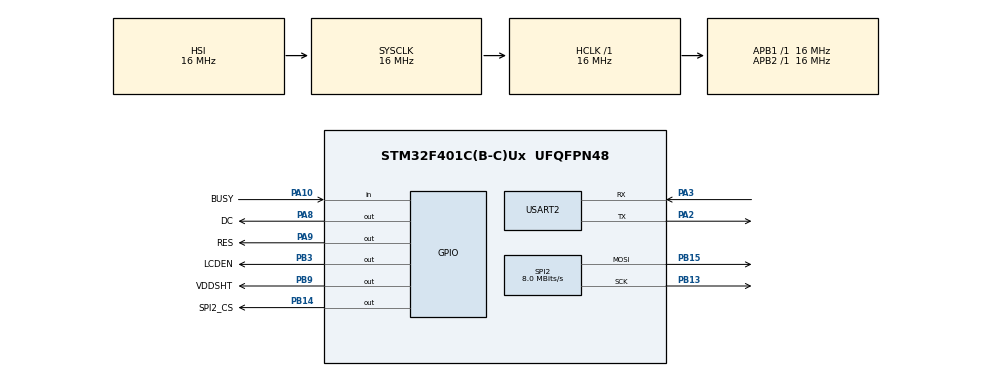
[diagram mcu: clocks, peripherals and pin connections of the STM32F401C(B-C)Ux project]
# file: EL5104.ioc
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Mcu.Family=STM32F4
Mcu.Name=STM32F401C(B-C)Ux
Mcu.Package=UFQFPN48
NVIC.PriorityGroup=NVIC_PRIORITYGROUP_4
NVIC.USART2_IRQn=true\:7\:0\:true\:false\:true\:true\:true
PA10.GPIO_Label=BUSY
PA10.GPIO_PuPd=GPIO_PULLUP
PA10.Signal=GPIO_Input
PA13.Mode=Serial_Wire
PA13.Signal=SYS_JTMS-SWDIO
PA14.Mode=Serial_Wire
PA14.Signal=SYS_JTCK-SWCLK
PA2.Mode=Asynchronous
PA2.Signal=USART2_TX
PA3.Mode=Asynchronous
PA3.Signal=USART2_RX
PA8.GPIO_Label=DC
PA8.Signal=GPIO_Output
PA9.GPIO_Label=RES
PA9.Signal=GPIO_Output
PB13.Mode=TX_Only_Simplex_Unidirect_Master
PB13.Signal=SPI2_SCK
PB14.GPIO_Label=SPI2_CS
PB14.Signal=GPIO_Output
PB15.Mode=TX_Only_Simplex_Unidirect_Master
PB15.Signal=SPI2_MOSI
PB3.GPIO_Label=LCDEN
PB3.GPIO_ModeDefaultOutputPP=GPIO_MODE_OUTPUT_PP
PB3.GPIO_PuPd=GPIO_NOPULL
PB3.PinState=GPIO_PIN_SET
PB3.Signal=GPIO_Output
PB6.Signal=I2C1_SCL
PB7.Signal=I2C1_SDA
PB9.GPIO_Label=VDDSHT
PB9.PinState=GPIO_PIN_SET
PB9.Signal=GPIO_Output
PC14-OSC32_IN.Mode=LSE-External-Oscillator
PC14-OSC32_IN.Signal=RCC_OSC32_IN
PC15-OSC32_OUT.Mode=LSE-External-Oscillator
PC15-OSC32_OUT.Signal=RCC_OSC32_OUT
ProjectManager.HeapSize=0x200
ProjectManager.StackSize=0x400
ProjectManager.TargetToolchain=MDK-ARM V5.27
RCC.AHBFreq_Value=16000000
RCC.APB1Freq_Value=16000000
RCC.APB2Freq_Value=16000000
RCC.CortexFreq_Value=16000000
RCC.HSE_VALUE=25000000
RCC.HSI_VALUE=16000000
RCC.SYSCLKFreq_VALUE=16000000
RCC.VCOOutputFreq_Value=192000000
SPI2.CalculateBaudRate=8.0 MBits/s
SPI2.Direction=SPI_DIRECTION_2LINES
SPI2.Mode=SPI_MODE_MASTER
SPI2.VirtualType=VM_MASTER
USART2.VirtualMode=VM_ASYNC
VP_RTC_VS_RTC_Activate.Mode=RTC_Enabled
VP_RTC_VS_RTC_Calendar.Mode=RTC_Calendar
board=custom

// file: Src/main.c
/* USER CODE BEGIN Header */
/**
  ******************************************************************************
  * @file           : main.c
  * @brief          : Main program body
  ******************************************************************************
  * @attention
  *
  * <h2><center>&copy; Copyright (c) 2020 STMicroelectronics.
  * All rights reserved.</center></h2>
  *
  * This software component is licensed by ST under BSD 3-Clause license,
  * the "License"; You may not use this file except in compliance with the
  * License. You may obtain a copy of the License at:
  *                        opensource.org/licenses/BSD-3-Clause
  *
  ******************************************************************************
  */
/* USER CODE END Header */

#include "main.h"
#include "rtc.h"
#include "spi.h"
#include "usart.h"
#include "gpio.h"

/* USER CODE BEGIN PV */
const uint8_t gImage_black1[15000];
/* USER CODE END PV */

void SystemClock_Config(void);

/* USER CODE BEGIN 0 */
void EPD_W21_WriteCMD(uint8_t cmd)
{
	HAL_GPIO_WritePin(GPIOB, SPI2_CS_Pin, GPIO_PIN_RESET);
	HAL_GPIO_WritePin(GPIOA, DC_Pin, GPIO_PIN_RESET);
	HAL_SPI_Transmit(&hspi2, &cmd, 1, 0xff);
	HAL_GPIO_WritePin(GPIOB, SPI2_CS_Pin, GPIO_PIN_SET);
}

void EPD_W21_WriteDATA(uint8_t dat)
{
	HAL_GPIO_WritePin(GPIOB, SPI2_CS_Pin, GPIO_PIN_RESET);
	HAL_GPIO_WritePin(GPIOA, DC_Pin, GPIO_PIN_SET);
	HAL_SPI_Transmit(&hspi2, &dat, 1, 0xff);
	HAL_GPIO_WritePin(GPIOB, SPI2_CS_Pin, GPIO_PIN_SET);
}

void lcd_chkstatus(void)
{
//	while(isEPD_W21_BUSY);  //1:BUSY,0:Free
//	HAL_Delay(200);
}

void EPD_init(void)
{
	  HAL_GPIO_WritePin(GPIOA, RES_Pin, GPIO_PIN_RESET);
    HAL_Delay(100);
	  HAL_GPIO_WritePin(GPIOA, RES_Pin, GPIO_PIN_SET);

  	EPD_W21_WriteCMD(0x12);			//SWRESET
		//lcd_chkstatus(); //waiting for the electronic paper IC to release the idle signal
	  HAL_Delay(100);
		EPD_W21_WriteCMD(0x74);
		EPD_W21_WriteDATA(0x54);
		EPD_W21_WriteCMD(0x7E);
		EPD_W21_WriteDATA(0x3B);
		EPD_W21_WriteCMD(0x2B);  // Reduce glitch under ACVCOM
		EPD_W21_WriteDATA(0x04);
		EPD_W21_WriteDATA(0x63);

		EPD_W21_WriteCMD(0x0C);  // Soft start setting
		EPD_W21_WriteDATA(0x8B);
		EPD_W21_WriteDATA(0x9C);
		EPD_W21_WriteDATA(0x96);
		EPD_W21_WriteDATA(0x0F);

		EPD_W21_WriteCMD(0x01);  // Set MUX as 300
		EPD_W21_WriteDATA(0x2B);
		EPD_W21_WriteDATA(0x01);
		EPD_W21_WriteDATA(0x00);

		EPD_W21_WriteCMD(0x11);  // Data entry mode
		EPD_W21_WriteDATA(0x01);
		EPD_W21_WriteCMD(0x44);
		EPD_W21_WriteDATA(0x00); // RAM x address start at 0
		EPD_W21_WriteDATA(0x31); // RAM x address end at 31h(49+1)*8->400
		EPD_W21_WriteCMD(0x45);
		EPD_W21_WriteDATA(0x2B);   // RAM y address start at 12Bh
		EPD_W21_WriteDATA(0x01);
		EPD_W21_WriteDATA(0x00); // RAM y address end at 00h
		EPD_W21_WriteDATA(0x00);
		EPD_W21_WriteCMD(0x3C); // board
		EPD_W21_WriteDATA(0x01); // HIZ

		EPD_W21_WriteCMD(0x18);
		EPD_W21_WriteDATA(0X80);
		EPD_W21_WriteCMD(0x22);
		EPD_W21_WriteDATA(0XB1);	//Load Temperature and waveform setting.
		EPD_W21_WriteCMD(0x20);
		//lcd_chkstatus(); //waiting for the electronic paper IC to release the idle signal
		HAL_Delay(400);

		EPD_W21_WriteCMD(0x4E);
		EPD_W21_WriteDATA(0x00);
		EPD_W21_WriteCMD(0x4F);
		EPD_W21_WriteDATA(0x2B);
		EPD_W21_WriteDATA(0x01);
}
void EPD_refresh(void)
{
		EPD_W21_WriteCMD(0x22);			//DISPLAY REFRESH
		EPD_W21_WriteDATA(0xC7);
		EPD_W21_WriteCMD(0x20);
		//lcd_chkstatus(); //waiting for the electronic paper IC to release the idle signal
		HAL_Delay(1000);
}
void EPD_sleep(void)
{
    EPD_W21_WriteCMD(0X10);  	//deep sleep
		EPD_W21_WriteDATA(0x01);
}

void PIC_display(const unsigned char* picData_BW,const unsigned char* picData_R)
{
    unsigned int i;
		EPD_W21_WriteCMD(0x24);	       //Transfer BW data
	  for(i=0;i<15000;i++)
	{
	  EPD_W21_WriteDATA(~(*picData_BW));
	  picData_BW++;
	}
		EPD_W21_WriteCMD(0x26);		     //Transfer RED data
	  for(i=0;i<15000;i++)
	{
	  EPD_W21_WriteDATA(0);
	  picData_R++;
	}

}
void PIC_display_Clean(void)
{
    unsigned int i;
		EPD_W21_WriteCMD(0x24);	       //Transfer BW data
	  for(i=0;i<15000;i++)
	{
	  EPD_W21_WriteDATA(0xff);
	}

		EPD_W21_WriteCMD(0x26);		     //Transfer RED data
	  for(i=0;i<15000;i++)
	{
	  EPD_W21_WriteDATA(0x00);
	}
}

/* USER CODE END 0 */

int main(void)
{

  /* MCU Configuration--------------------------------------------------------*/

  /* Reset of all peripherals, Initializes the Flash interface and the Systick. */
  HAL_Init();

  /* Configure the system clock */
  SystemClock_Config();

  /* Initialize all configured peripherals */
  MX_GPIO_Init();
  MX_RTC_Init();
  MX_SPI2_Init();
  MX_USART2_UART_Init();
  /* USER CODE BEGIN 2 */
  HAL_GPIO_WritePin(GPIOB, LCDEN_Pin, GPIO_PIN_RESET);
  /* USER CODE END 2 */

  /* Infinite loop */
  /* USER CODE BEGIN WHILE */
	EPD_init(); //EPD init
	PIC_display(gImage_black1,gImage_black1);//EPD_picture1
	EPD_refresh();//EPD_refresh
	EPD_sleep();//EPD_sleep,Sleep instruction is necessary, please do not delete!!!
	HAL_Delay(80);
  while (1)
  {

		//EPD_Clean
//		EPD_init(); //EPD init
//	  PIC_display_Clean();//EPD_Clean
//		EPD_refresh();//EPD_refresh
//		EPD_sleep();//EPD_sleep,Sleep instruction is necessary, please do not delete!!!
//		HAL_Delay(80);
    /* USER CODE END WHILE */

  }
}

void SystemClock_Config(void)
{
  RCC_OscInitTypeDef RCC_OscInitStruct = {0};
  RCC_ClkInitTypeDef RCC_ClkInitStruct = {0};
  RCC_PeriphCLKInitTypeDef PeriphClkInitStruct = {0};

  /** Configure the main internal regulator output voltage
  */
  __HAL_RCC_PWR_CLK_ENABLE();
  __HAL_PWR_VOLTAGESCALING_CONFIG(PWR_REGULATOR_VOLTAGE_SCALE2);
  /** Initializes the CPU, AHB and APB busses clocks
  */
  RCC_OscInitStruct.OscillatorType = RCC_OSCILLATORTYPE_HSI|RCC_OSCILLATORTYPE_LSI;
  RCC_OscInitStruct.HSIState = RCC_HSI_ON;
  RCC_OscInitStruct.HSICalibrationValue = RCC_HSICALIBRATION_DEFAULT;
  RCC_OscInitStruct.LSIState = RCC_LSI_ON;
  RCC_OscInitStruct.PLL.PLLState = RCC_PLL_NONE;
  if (HAL_RCC_OscConfig(&RCC_OscInitStruct) != HAL_OK)
  {
    Error_Handler();
  }
  /** Initializes the CPU, AHB and APB busses clocks
  */
  RCC_ClkInitStruct.ClockType = RCC_CLOCKTYPE_HCLK|RCC_CLOCKTYPE_SYSCLK
                              |RCC_CLOCKTYPE_PCLK1|RCC_CLOCKTYPE_PCLK2;
  RCC_ClkInitStruct.SYSCLKSource = RCC_SYSCLKSOURCE_HSI;
  RCC_ClkInitStruct.AHBCLKDivider = RCC_SYSCLK_DIV1;
  RCC_ClkInitStruct.APB1CLKDivider = RCC_HCLK_DIV1;
  RCC_ClkInitStruct.APB2CLKDivider = RCC_HCLK_DIV1;

  if (HAL_RCC_ClockConfig(&RCC_ClkInitStruct, FLASH_LATENCY_0) != HAL_OK)
  {
    Error_Handler();
  }
  PeriphClkInitStruct.PeriphClockSelection = RCC_PERIPHCLK_RTC;
  PeriphClkInitStruct.RTCClockSelection = RCC_RTCCLKSOURCE_LSI;
  if (HAL_RCCEx_PeriphCLKConfig(&PeriphClkInitStruct) != HAL_OK)
  {
    Error_Handler();
  }
}

/* USER CODE BEGIN 4 */
const uint8_t gImage_black1[15000]  = {
0X00,0X00,0X04,0X14,0X22,0X78,0X00,0X04,0X10,0X00,0X00,0X43,0X06,0X80,0X0E,0X05,
0X04,0X22,0X10,0X00,0X89,0X04,0X00,0X40,0X00,0X30,0X09,0X08,0X80,0X84,0X00,0X48,
0X22,0XA0,0X00,0X09,0X04,0X08,0X03,0X04,0X00,0X0E,0X00,0X00,0X00,0X00,0X00,0X00,
0X00,0X00,0X00,0X00,0X0E,0X2C,0XA2,0X78,0X01,0X02,0X80,0X00,0X02,0X46,0X04,0X08,
0X07,0X06,0X00,0X02,0X80,0X20,0X80,0X03,0X00,0X08,0X05,0X08,0X08,0X40,0X40,0X0E,
0X0C,0X02,0X23,0X50,0X11,0X88,0X48,0X00,0X01,0XE8,0X08,0X06,0X00,0X00,0X00,0X00,
0X00,0X00,0X00,0X00,0X00,0X00,0X1E,0XBA,0X12,0XE0,0X00,0X10,0X44,0X88,0X00,0X04,
0X0C,0X00,0X0E,0X50,0XC0,0XA0,0X00,0X50,0X94,0X00,0X00,0X02,0X02,0X23,0X08,0X02,
0XC0,0X04,0X01,0X04,0X09,0X11,0X01,0X04,0X04,0X00,0X00,0XD8,0X22,0X07,0X00,0X00,
0X00,0X00,0X00,0X00,0X00,0X00,0X00,0X00,0X1C,0X1D,0X60,0XE0,0X25,0X26,0XE0,0X01,
0X00,0X08,0X18,0X20,0X87,0X00,0X00,0X00,0X81,0X01,0X30,0X0A,0X20,0X02,0X84,0X42,
0X00,0X80,0X00,0X03,0X00,0X00,0X0B,0X04,0X00,0X04,0X00,0X04,0X10,0XE0,0X00,0X07,
0X00,0X00,0X00,0X00,0X00,0X00,0X00,0X00,0X00,0X00,0X1E,0X40,0X29,0XC0,0X01,0X0B,
0X87,0X02,0X0E,0X00,0X98,0X40,0X0F,0X02,0X00,0X40,0X24,0X00,0X06,0X4C,0X60,0X10,
0X20,0X20,0X40,0X00,0X00,0X01,0X00,0X11,0X10,0X80,0X00,0X89,0X42,0X00,0X10,0X74,
0X10,0X07,0X80,0X00,0X00,0X00,0X00,0X00,0X00,0X00,0X00,0X00,0X39,0X40,0X12,0XE0,
0XB3,0X82,0XC1,0X91,0X60,0X01,0X19,0X00,0X06,0X00,0X00,0X50,0XD4,0X88,0X00,0X01,
0X40,0X10,0X00,0X02,0X00,0X00,0X02,0X02,0X80,0X40,0X14,0X88,0X80,0X00,0X00,0X10,
0X80,0X78,0X00,0X17,0X80,0X00,0X00,0X00,0X00,0X00,0X00,0X00,0X00,0X00,0X3A,0X24,
0X11,0XC0,0X04,0X56,0X08,0X10,0X80,0X88,0X18,0X00,0X06,0X20,0X15,0X08,0X00,0X00,
0X00,0X20,0X0B,0X00,0X00,0X00,0X1C,0X20,0X19,0X82,0X30,0X00,0X04,0XC0,0X22,0X00,
0X10,0X00,0X00,0X68,0X0C,0X83,0X80,0X00,0X00,0X00,0X00,0X00,0X00,0X00,0X00,0X00,
0X1A,0XBE,0X1F,0X80,0X10,0X00,0XC6,0X08,0X05,0X00,0X30,0X00,0X07,0X04,0X00,0X68,
0XC0,0X40,0X04,0X01,0X00,0X40,0X80,0X00,0X04,0X00,0X08,0X08,0X08,0X05,0X04,0X42,
0X00,0X01,0X21,0X08,0X00,0X38,0X00,0X01,0XC0,0X00,0X00,0X00,0X00,0X00,0X00,0X00,
0X00,0X00,0X3C,0X18,0X4B,0XC0,0X00,0X92,0XEC,0X61,0X8A,0X04,0X35,0X04,0X67,0X00,
0X00,0X04,0X00,0X00,0X04,0X01,0X00,0X00,0X0C,0X10,0X00,0X09,0X1A,0X2A,0X12,0X44,
0X01,0XE8,0X90,0X2C,0X02,0X01,0X04,0X1E,0XE4,0X31,0XC0,0X00,0X00,0X00,0X00,0X00,
0X00,0X00,0X00,0X00,0X38,0X24,0XA7,0X01,0X00,0X00,0X48,0X02,0X00,0X00,0X30,0X00,
0XFF,0X02,0XC0,0X20,0X80,0X00,0X04,0X00,0X00,0X41,0X83,0X00,0X01,0X00,0X80,0X00,
0X00,0X01,0X01,0X60,0X90,0X00,0X00,0X00,0X00,0X0E,0X04,0X45,0XC0,0X00,0X00,0X00,
0X00,0X00,0X00,0X00,0X00,0X00,0X3A,0X20,0X4F,0X00,0X03,0X0C,0X61,0X00,0X80,0X01,
0X40,0X00,0X0F,0X10,0X29,0X01,0X00,0X48,0X00,0X0C,0X24,0X30,0X08,0X50,0X02,0X04,
0X00,0X01,0X00,0X00,0X00,0X70,0X20,0X10,0XC2,0X02,0X04,0X5E,0X85,0X80,0XE0,0X00,
0X00,0X00,0X00,0X00,0X00,0X00,0X00,0X00,0XBC,0X55,0X2E,0X01,0X00,0X98,0X01,0X01,
0XC2,0X00,0X40,0X00,0X47,0X20,0XA0,0X10,0X00,0X00,0X04,0X80,0X22,0X01,0X00,0X10,
0X02,0X00,0X00,0X23,0X00,0X00,0X50,0X30,0X02,0X10,0X00,0X04,0X20,0X5F,0X43,0X00,
0XE0,0X00,0X00,0X00,0X00,0X00,0X00,0X00,0X00,0X00,0X38,0X10,0X7C,0X00,0X01,0X05,
0X82,0X80,0X82,0X88,0X60,0X08,0X07,0X84,0X00,0X00,0X40,0X00,0X80,0X21,0X02,0X90,
0X00,0X00,0X02,0X02,0X00,0X03,0X24,0X00,0X88,0X10,0X00,0X00,0X08,0X01,0X30,0X17,
0X20,0X00,0X60,0X00,0X00,0X00,0X00,0X00,0X00,0X00,0X00,0X00,0X38,0XB4,0X5E,0X00,
0X05,0X11,0X00,0X00,0X00,0X02,0XC0,0X00,0X1F,0XA0,0X00,0X02,0X41,0X20,0X83,0X02,
0X00,0X11,0X00,0X28,0X4B,0X01,0X04,0X03,0X02,0X00,0X00,0X90,0X03,0X00,0X00,0X40,
0X90,0X47,0X80,0X80,0X70,0X00,0X00,0X00,0X00,0X00,0X00,0X00,0X00,0X00,0X38,0XD6,
0XDC,0X00,0X25,0X9C,0X62,0X01,0X28,0X00,0XC0,0X40,0X0F,0X88,0X00,0X00,0X00,0X20,
0X80,0X00,0X10,0X10,0X84,0X00,0X02,0X44,0XAA,0X41,0X80,0X00,0X00,0XB8,0X08,0X00,
0X08,0X06,0X04,0X03,0XCA,0X80,0X70,0X00,0X00,0X00,0X00,0X00,0X00,0X00,0X00,0X00,
0X1C,0X45,0X9C,0X00,0X40,0X00,0X00,0X00,0X05,0X00,0X84,0X04,0X8B,0X80,0X00,0X0C,
0X10,0X01,0X00,0X10,0X00,0X60,0X80,0X04,0X03,0X21,0X00,0X25,0X80,0X0D,0X08,0X18,
0X12,0X80,0X00,0X05,0X04,0X01,0XE0,0X80,0X30,0X00,0X00,0X00,0X00,0X00,0X00,0X00,
0X00,0X00,0X1D,0X2E,0X38,0X04,0X00,0XFD,0XC8,0X00,0X04,0X01,0X80,0X06,0X1B,0X80,
0X00,0X00,0X08,0X00,0X10,0X80,0X00,0X02,0XA6,0X40,0X02,0X00,0X00,0X43,0XE0,0X00,
0X04,0X0C,0X00,0X14,0X00,0X82,0X01,0X01,0XE0,0XC0,0X78,0X00,0X00,0X00,0X00,0X00,
0X00,0X00,0X00,0X00,0X1E,0X8A,0XB8,0X00,0X0D,0X08,0X54,0X10,0X04,0X01,0X01,0X45,
0X07,0X80,0X61,0X01,0X00,0X02,0X06,0X30,0X00,0X50,0X20,0X08,0X03,0X02,0X00,0X01,
0X84,0X01,0X00,0X4D,0X04,0X24,0X00,0X00,0X00,0X00,0XD1,0X60,0X30,0X00,0X00,0X00,
0X00,0X00,0X00,0X00,0X00,0X00,0X0E,0X80,0X70,0X00,0X00,0X00,0XA4,0X01,0X10,0X03,
0X90,0X02,0XC3,0XC0,0X40,0X00,0XA0,0X08,0X80,0X20,0X42,0XB0,0X3A,0X00,0X03,0X00,
0X00,0X81,0XC0,0X12,0X00,0X5C,0X02,0X00,0X01,0X84,0X08,0X80,0X98,0XC0,0X38,0X00,
0X00,0X00,0X00,0X00,0X00,0X00,0X00,0X00,0X1E,0X9E,0X70,0X00,0X09,0X01,0X52,0X10,
0X00,0X01,0XA0,0X20,0X8D,0XD0,0X00,0X90,0X70,0XB5,0X5A,0X00,0X00,0X08,0X2E,0X40,
0X03,0X30,0X08,0X03,0XE0,0X02,0X00,0X26,0X00,0X40,0X90,0X40,0X04,0X00,0XDC,0X20,
0X38,0X00,0X00,0X00,0X00,0X00,0X00,0X00,0X00,0X00,0X00,0X5B,0XF0,0X00,0X01,0XCA,
0X53,0X80,0X08,0XCB,0X04,0X21,0X81,0XC0,0X04,0X04,0X00,0X50,0X42,0X40,0X08,0X00,
0X08,0X00,0X03,0X58,0X82,0XC1,0XE5,0X00,0X00,0X02,0X01,0X08,0X20,0X20,0X55,0X14,
0XCC,0X38,0X18,0X00,0X00,0X00,0X00,0X00,0X00,0X00,0X00,0X00,0X0F,0X25,0XF0,0X00,
0X01,0X39,0X44,0X18,0X2C,0X83,0X02,0X15,0X09,0XC0,0X12,0X88,0X00,0X04,0X10,0X40,
0X00,0X00,0X10,0X80,0X03,0X82,0X39,0X01,0XF8,0X00,0X00,0X07,0X80,0X20,0X00,0X09,
0X40,0X04,0X8E,0X12,0X1C,0X00,0X00,0X00,0X00,0X00,0X00,0X00,0X00,0X00,0X47,0X86,
0XE8,0X00,0X05,0X45,0X18,0X84,0X8A,0X07,0X00,0X13,0X00,0XC8,0X00,0X01,0X90,0X01,
0X80,0X00,0X00,0X48,0X08,0X00,0X15,0X81,0X10,0X01,0XFC,0X12,0X20,0X03,0X00,0X00,
0X28,0X11,0X80,0X00,0X47,0X10,0X0C,0X00,0X00,0X00,0X00,0X00,0X00,0X00,0X00,0X00,
0X23,0XC6,0XE0,0X40,0X00,0X10,0XC2,0X00,0X08,0X06,0X08,0X06,0X10,0XE8,0X04,0X0A,
0X00,0X02,0X20,0X02,0X26,0X0C,0X08,0X01,0X09,0XB0,0X00,0X03,0X98,0X10,0X00,0X01,
0X80,0X40,0X04,0X20,0X0A,0X00,0X4B,0X58,0X0C,0X00,0X00,0X00,0X00,0X00,0X00,0X00,
0X00,0X00,0X03,0X89,0XE0,0X00,0X80,0XE0,0X05,0X00,0X4C,0X16,0X36,0X3C,0X03,0XC0,
0X11,0X04,0X00,0X02,0X02,0X80,0X80,0X04,0X02,0X04,0X03,0X80,0X80,0X03,0XBC,0X00,
0X00,0X13,0X00,0X20,0X0A,0X20,0X40,0X01,0X61,0XCC,0X0C,0X00,0X00,0X00,0X00,0X00,
0X00,0X00,0X00,0X00,0X41,0XDD,0XE0,0X00,0X10,0X10,0XA2,0X08,0X18,0X06,0X48,0X0C,
0X05,0XE0,0X24,0X24,0X00,0X0A,0X40,0X00,0X00,0X45,0X10,0X10,0X49,0X88,0X00,0X03,
0XDE,0X20,0X42,0X11,0X80,0X00,0X08,0X31,0X04,0X00,0X61,0XCE,0X06,0X00,0X00,0X00,
0X00,0X00,0X00,0X00,0X00,0X00,0X01,0XD3,0XC0,0X00,0X00,0X0B,0X90,0X31,0X10,0X0E,
0X04,0X18,0X01,0XE0,0X00,0X03,0X00,0X24,0X8A,0X00,0X00,0X04,0X08,0X00,0X09,0X80,
0X00,0X01,0XCE,0X04,0X00,0X01,0X84,0X04,0X00,0X01,0X46,0X00,0XE0,0XC4,0XAE,0X00,
0X00,0X00,0X00,0X00,0X00,0X00,0X00,0X00,0X00,0XF3,0X88,0X10,0X20,0X46,0X17,0X80,
0X10,0X04,0X60,0X1A,0X03,0XE0,0X01,0X16,0X02,0X01,0X22,0X00,0X00,0X44,0X82,0X09,
0X23,0XE0,0X00,0X11,0XCF,0X00,0X04,0X02,0XC2,0X00,0X00,0X00,0X02,0X10,0X30,0X26,
0X06,0X00,0X00,0X00,0X00,0X00,0X00,0X00,0X00,0X00,0X00,0XF7,0X80,0X11,0X02,0X2E,
0X11,0X80,0X50,0X46,0X41,0X74,0X43,0X40,0X14,0X02,0X00,0X10,0X62,0X40,0X88,0X15,
0X04,0X08,0X83,0X80,0X04,0X01,0XC6,0X00,0X48,0X00,0XC4,0X20,0X00,0X00,0X00,0X40,
0X18,0X33,0X16,0X00,0X00,0X00,0X00,0X00,0X00,0X00,0X00,0X00,0X00,0X7F,0XC0,0X00,
0X01,0X38,0X00,0X04,0X80,0X8E,0X00,0XB4,0XA7,0X64,0X20,0X02,0X03,0X41,0X00,0X00,
0X00,0X0E,0X0C,0X10,0X03,0XC0,0X00,0X01,0XCB,0X40,0X20,0X00,0X50,0X00,0X00,0X04,
0X00,0X00,0X9A,0X1A,0X03,0X80,0X00,0X00,0X00,0X00,0X00,0X00,0X00,0X00,0X00,0X7F,
0X00,0X04,0X00,0X04,0X02,0X02,0X12,0X0C,0X82,0X60,0X0E,0XE1,0X04,0X0E,0X00,0X20,
0X00,0X00,0X10,0X06,0X10,0X80,0X17,0XC8,0X80,0X01,0XCB,0X00,0X40,0X01,0X50,0X50,
0X00,0X80,0XA0,0X10,0X1C,0X0D,0X83,0X80,0X00,0X00,0X00,0X00,0X00,0X00,0X00,0X00,
0X00,0X3F,0X02,0X00,0X00,0X01,0X85,0X02,0X00,0X0C,0X09,0X41,0X1F,0X70,0X02,0X02,
0X20,0X24,0X20,0X00,0X10,0X0A,0X51,0X04,0X47,0XC0,0X00,0X09,0X81,0X80,0X00,0X4A,
0XE9,0X00,0X01,0X10,0X21,0X00,0X2C,0X87,0X83,0X00,0X00,0X00,0X00,0X00,0X00,0X00,
0X00,0X00,0X00,0X3C,0X00,0X00,0X08,0X06,0X41,0X00,0XA0,0X8C,0X00,0XC0,0X1C,0X70,
0X03,0X11,0X02,0X20,0X20,0X80,0X40,0X47,0X40,0X10,0X03,0XE2,0X00,0X07,0X8B,0X81,
0X00,0X00,0X79,0X00,0X00,0X04,0X05,0X94,0X8D,0X17,0X93,0X80,0X00,0X00,0X00,0X00,
0X00,0X00,0X00,0X00,0X00,0X3E,0X08,0X19,0X00,0X02,0X10,0X80,0X00,0X08,0X19,0X8A,
0X1C,0X30,0X06,0X01,0X88,0X28,0X81,0X20,0X00,0X03,0X02,0X00,0X03,0XCA,0X40,0X01,
0X81,0XC4,0X00,0X04,0X60,0X00,0X00,0X40,0X28,0X80,0X0E,0X03,0XD3,0X80,0X00,0X00,
0X00,0X00,0X00,0X00,0X00,0X00,0X00,0X3C,0X08,0X50,0X80,0X01,0X00,0X80,0X22,0X09,
0X01,0X80,0X39,0X70,0X00,0X08,0X0C,0X00,0X11,0X01,0X20,0X05,0X0A,0X00,0X43,0XC0,
0X00,0X13,0X83,0XE0,0X30,0X04,0X2C,0X00,0X00,0X00,0X62,0X80,0X06,0X11,0XC3,0XC0,
0X00,0X00,0X00,0X00,0X00,0X00,0X00,0X00,0X00,0X72,0X00,0X23,0X04,0X20,0X78,0X82,
0X20,0X1B,0X8A,0X00,0X39,0X78,0X01,0X16,0X02,0X48,0X40,0X00,0X00,0X15,0X00,0X01,
0X13,0XC0,0X00,0X03,0X80,0XE0,0X00,0X01,0XB8,0X18,0X00,0X20,0X60,0X80,0X07,0X00,
0XC3,0XE0,0X00,0X00,0X00,0X00,0X00,0X00,0X00,0X00,0X00,0X70,0X00,0X00,0X00,0X08,
0XE4,0X10,0X64,0X1A,0X27,0X10,0X30,0XF0,0X00,0X01,0X42,0X01,0X28,0X20,0X10,0X15,
0X11,0X08,0X07,0XC0,0X10,0X83,0X80,0XE4,0X00,0X3A,0X92,0X00,0X20,0X00,0X00,0XA0,
0X07,0X60,0XE5,0XA0,0X00,0X00,0X00,0X00,0X00,0X00,0X00,0X00,0X00,0X78,0X00,0X10,
0X30,0X00,0XC6,0X50,0X28,0X1C,0X04,0X82,0X70,0XB8,0X00,0X00,0X00,0X04,0XA0,0X18,
0X00,0X09,0X88,0X00,0X03,0XC0,0X10,0X13,0XA0,0XE4,0X04,0X80,0X18,0X90,0X00,0X03,
0X10,0XC4,0X07,0X80,0X31,0XE0,0X00,0X00,0X00,0X00,0X00,0X00,0X00,0X00,0X00,0XE0,
0X01,0X00,0X00,0X00,0X21,0X90,0X22,0XDC,0X44,0X08,0XE2,0X5C,0X00,0X00,0XA4,0X0A,
0X30,0X00,0X00,0XAD,0X00,0X01,0X27,0XF4,0X08,0X03,0X91,0X70,0X08,0X02,0X18,0X20,
0X00,0X00,0X8A,0X4C,0X43,0X20,0X30,0XC0,0X00,0X00,0X00,0X00,0X00,0X00,0X00,0X00,
0X01,0XE0,0X20,0X80,0X40,0X00,0X00,0X80,0X20,0X58,0X8C,0X01,0XE4,0X58,0X00,0X01,
0X18,0X10,0X10,0X00,0X04,0X05,0X00,0X00,0X07,0XE0,0XB2,0X23,0X92,0X72,0X00,0X00,
0X12,0X00,0X03,0X40,0X40,0X22,0X03,0XE2,0X5D,0XF0,0X00,0X00,0X00,0X00,0X00,0X00,
0X00,0X00,0X01,0XC0,0X00,0X60,0X40,0X08,0X01,0X80,0X20,0X3C,0X08,0X01,0XC1,0XB8,
0X02,0X12,0X0A,0X80,0X10,0X18,0X8F,0X07,0X00,0XA0,0X07,0XE0,0X41,0X23,0XCE,0XF8,
0X00,0X01,0X1C,0X00,0X02,0X00,0X08,0X20,0X81,0XC0,0X28,0XE0,0X00,0X00,0X00,0X00,
0X00,0X00,0X00,0X00,0X03,0XC0,0X00,0X00,0X00,0X28,0X02,0X00,0X00,0X30,0X50,0X83,
0X83,0X5C,0X00,0XCC,0X81,0X00,0X53,0X00,0X40,0X1D,0X32,0X00,0X06,0X70,0X01,0X03,
0X1A,0X38,0X08,0X00,0X8C,0X00,0X20,0X06,0X80,0X78,0X01,0XEA,0X86,0XF0,0X00,0X00,
0X00,0X00,0X00,0X00,0X00,0X00,0X23,0XC0,0X00,0X00,0X04,0X00,0X00,0X0A,0X40,0X3C,
0X90,0X07,0X81,0X1C,0X48,0X60,0XC3,0X00,0X88,0X00,0XF1,0X05,0X80,0X03,0X05,0X65,
0X20,0X83,0X39,0X18,0X00,0X00,0X18,0X00,0X1A,0X10,0X20,0X20,0X08,0XF0,0X02,0XF0,
0X00,0X00,0X00,0X00,0X00,0X00,0X00,0X00,0X0F,0X80,0X0B,0X00,0X04,0X00,0X08,0X00,
0X60,0X70,0X60,0X0F,0X41,0XDC,0X05,0X82,0X80,0XC0,0X28,0X00,0X04,0X0E,0XC0,0X06,
0X8E,0XE0,0X80,0X03,0X20,0X1C,0X00,0X12,0X1E,0X60,0X40,0X00,0X00,0X20,0X00,0XF8,
0X30,0XF8,0X00,0X00,0X00,0X00,0X00,0X00,0X00,0X00,0X0F,0X80,0X08,0X00,0X00,0X01,
0X00,0X00,0XA8,0X70,0X70,0X4E,0X40,0X1C,0X02,0X91,0XC2,0XC0,0X00,0X80,0X80,0X0C,
0X20,0X08,0X0E,0X71,0X20,0X13,0X00,0X9F,0X00,0X40,0X0C,0X01,0X03,0X80,0X00,0X30,
0X10,0XFC,0X04,0XF0,0X00,0X00,0X00,0X00,0X00,0X00,0X00,0X00,0X0F,0X08,0X08,0X20,
0X00,0X00,0X00,0X02,0X44,0X30,0X60,0X96,0X07,0XAE,0X01,0X00,0X53,0X40,0X04,0X20,
0X40,0X26,0X00,0X00,0X0E,0X68,0X09,0X07,0X08,0X0C,0X0A,0X00,0X1C,0X80,0X02,0X00,
0X40,0X94,0X80,0XFC,0X0C,0XF8,0X00,0X00,0X00,0X00,0X00,0X00,0X00,0X00,0X3E,0X00,
0X83,0X02,0X20,0X70,0X00,0X04,0XC0,0X30,0X40,0X1A,0X0A,0X0C,0X00,0X01,0X40,0X70,
0X05,0X00,0X00,0X0D,0X90,0X20,0X0E,0X70,0X08,0X07,0X02,0X0C,0X20,0X02,0X4C,0X00,
0X80,0X40,0X84,0X00,0X20,0X7E,0X00,0X78,0X00,0X00,0X00,0X00,0X00,0X00,0X00,0X00,
0XBE,0X11,0X04,0X00,0X00,0X00,0X40,0X00,0X00,0X34,0XC1,0X3D,0X60,0X46,0X00,0X40,
0XC0,0X20,0X04,0X00,0XC0,0X0F,0X00,0X01,0X0E,0X60,0X00,0X27,0X50,0XDE,0X00,0X42,
0X4C,0X42,0X00,0X00,0X00,0X98,0X04,0X7F,0X00,0X38,0X00,0X00,0X00,0X00,0X00,0X00,
0X00,0X00,0X7C,0X00,0X28,0X88,0X00,0X11,0X00,0X00,0X04,0X37,0XC0,0X5E,0X27,0X86,
0X00,0X80,0XC0,0X38,0X0B,0X80,0X00,0X0D,0X04,0X04,0X1C,0X70,0X41,0X87,0X04,0X0F,
0X00,0X02,0X9E,0X08,0X00,0X08,0X10,0X18,0X08,0X37,0X88,0X7C,0X00,0X00,0X00,0X00,
0X00,0X00,0X00,0X00,0X78,0X41,0X03,0X30,0X24,0X00,0X10,0X08,0XD8,0X79,0X80,0X7A,
0X28,0X46,0X00,0X00,0X67,0X0C,0X03,0X00,0X00,0X0D,0X80,0X00,0X5D,0X60,0X04,0X06,
0X52,0X53,0X09,0X10,0X06,0X11,0X01,0X00,0X18,0X1A,0X18,0X3F,0XA2,0X3C,0X00,0X00,
0X00,0X00,0X00,0X00,0X00,0X00,0XF0,0X00,0XA2,0X12,0X03,0X08,0X00,0X00,0X80,0X78,
0X90,0X54,0X1A,0X9F,0X02,0X10,0X48,0X04,0X1B,0X00,0X10,0X0C,0XA4,0X09,0X1C,0X60,
0X0C,0X07,0X90,0X57,0X28,0X00,0X2C,0X00,0X00,0X18,0X20,0X00,0X00,0X39,0X82,0X1E,
0X00,0X00,0X00,0X00,0X00,0X00,0X00,0X00,0XE0,0X04,0X14,0X84,0XA4,0X01,0X40,0X21,
0X01,0X31,0X93,0XF6,0X80,0X07,0X15,0X28,0XE0,0X46,0X51,0X82,0X10,0X04,0XA0,0X00,
0XDF,0X30,0X00,0X06,0X0C,0X67,0X90,0X88,0X06,0X44,0X02,0X00,0X0A,0X08,0X20,0X18,
0XE0,0X0F,0X00,0X00,0X00,0X00,0X00,0X00,0X00,0X01,0XE0,0X03,0X00,0X64,0X04,0X00,
0X00,0X11,0X00,0X39,0X41,0XE4,0X08,0X4F,0X18,0X44,0XE0,0X0A,0X00,0X00,0X82,0X2C,
0X88,0X00,0X18,0X70,0X94,0X8F,0X80,0X03,0X8C,0X00,0X86,0X80,0X00,0X00,0X12,0X08,
0X04,0X14,0XE1,0X06,0X00,0X00,0X00,0X00,0X00,0X00,0X00,0X03,0XC2,0X00,0X09,0X01,
0X50,0X00,0X02,0X01,0X00,0X63,0X61,0XC4,0X22,0X83,0XB0,0X02,0X62,0X03,0X04,0XC1,
0X20,0X2C,0X00,0X58,0X19,0X70,0X40,0X2E,0X04,0X13,0X84,0X08,0X06,0X00,0X12,0X22,
0X01,0X08,0X00,0X1C,0X75,0X47,0X80,0X00,0X00,0X00,0X00,0X00,0X00,0X07,0XE0,0X08,
0X00,0X08,0X00,0X00,0X0A,0X44,0X11,0X37,0X03,0XC0,0X11,0X82,0X02,0X00,0X43,0X01,
0X01,0X80,0X41,0XAC,0X80,0X00,0X3A,0X30,0X00,0X0E,0X00,0XF1,0XC0,0X00,0X4E,0X00,
0X00,0X00,0X00,0X28,0X00,0X1C,0X38,0X03,0X80,0X00,0X00,0X00,0X00,0X00,0X00,0X0F,
0X80,0X00,0X00,0X00,0X01,0X08,0X10,0X01,0X00,0X62,0X03,0XC2,0X83,0X25,0X81,0X00,
0X72,0X04,0XC2,0X81,0X00,0X0E,0XC4,0X00,0X18,0X72,0X0C,0X0E,0X20,0XC5,0XC8,0X00,
0X06,0X02,0X20,0X00,0X20,0X11,0X08,0X0D,0X9C,0X03,0X80,0X00,0X00,0X00,0X00,0X00,
0X00,0X0E,0X01,0X08,0XD0,0X00,0X00,0X00,0X40,0X09,0X40,0XF0,0X07,0X56,0XC0,0XC2,
0X80,0X08,0X60,0X10,0XC0,0X28,0X00,0X0C,0X84,0XC1,0X98,0X60,0X08,0X1E,0X12,0X00,
0XC0,0X05,0X03,0X28,0X00,0X20,0X00,0X08,0XC0,0X2C,0X4E,0X03,0XC0,0X00,0X00,0X00,
0X00,0X00,0X00,0X1E,0X01,0X02,0X00,0X09,0X82,0X20,0X40,0X23,0X00,0XE4,0X47,0X08,
0X9C,0X11,0XC4,0X80,0X70,0X00,0X20,0X30,0X00,0X08,0X84,0X30,0X34,0X31,0X00,0X0E,
0X99,0X08,0XE0,0X00,0X03,0X00,0X20,0X04,0X00,0X4A,0X00,0X06,0X8F,0X21,0XC0,0X00,
0X00,0X00,0X00,0X00,0X00,0X3C,0X00,0XC1,0X02,0X0A,0X80,0X20,0X00,0XAD,0X00,0X65,
0X0E,0X1A,0X18,0XA3,0X91,0X00,0X30,0X00,0X39,0X90,0X00,0X0C,0X10,0X00,0X32,0X78,
0X80,0X18,0X22,0X08,0XE0,0X01,0X13,0X00,0X00,0X28,0X84,0X50,0X60,0X06,0X07,0XA3,
0XE0,0X00,0X00,0X00,0X00,0X00,0X00,0X78,0X00,0X02,0X00,0X08,0X40,0X80,0X00,0X01,
0X00,0X7E,0X4E,0X33,0X59,0XD5,0XF1,0X07,0X64,0X00,0X18,0X18,0X00,0X08,0XA0,0X00,
0X34,0X30,0X10,0X1C,0X81,0X00,0X70,0X00,0X0A,0X02,0X04,0X10,0X40,0X08,0X08,0X84,
0X05,0XE0,0X70,0X00,0X00,0X00,0X00,0X00,0X00,0XB0,0X08,0X58,0X57,0X00,0X02,0X00,
0X03,0X01,0X04,0X7F,0X1C,0X19,0X40,0X01,0X91,0X01,0X30,0X80,0X08,0X8C,0X00,0X0C,
0X90,0X05,0X34,0XA0,0X28,0X0C,0X98,0X00,0X70,0X00,0X03,0X47,0X00,0X02,0X04,0X08,
0X91,0X43,0X12,0XF0,0X30,0X00,0X00,0X00,0X00,0X00,0X01,0XE0,0X90,0X40,0X80,0XD0,
0X00,0X32,0X04,0X02,0X00,0XF4,0XF8,0X56,0X88,0X12,0XE0,0X42,0X34,0X10,0X0C,0X04,
0X00,0X19,0X81,0X91,0X60,0X70,0X8A,0X38,0X00,0X42,0X71,0X84,0X03,0X03,0X48,0X00,
0X00,0X09,0XC1,0X43,0X00,0XF8,0X38,0X00,0X00,0X00,0X00,0X00,0X03,0XE1,0X00,0X11,
0XA0,0X90,0X40,0X84,0XC5,0X03,0X04,0X7C,0X7D,0X02,0X10,0X24,0XC1,0X32,0X70,0X0A,
0X26,0X5D,0X00,0X1B,0X84,0X40,0X61,0XB0,0X82,0X38,0X21,0X85,0X78,0X44,0X03,0X11,
0X0A,0X04,0X06,0X0C,0XC1,0X03,0X90,0X3C,0X1C,0X00,0X00,0X00,0X00,0X00,0X07,0X90,
0X01,0X25,0X81,0X19,0X88,0X60,0X01,0XA3,0X80,0XF2,0XBC,0X40,0X50,0X02,0XF0,0X09,
0XB0,0X00,0X06,0X02,0X02,0X1C,0XC0,0X90,0X60,0XF0,0X51,0X7C,0X80,0X20,0X38,0X00,
0X71,0X00,0X80,0X02,0X80,0X48,0XC0,0X03,0XC2,0X3D,0X0E,0X00,0X00,0X00,0X00,0X00,
0X0F,0X80,0X00,0X2F,0X80,0X10,0X01,0X00,0X02,0X07,0X00,0XF0,0X76,0X04,0X00,0X90,
0X61,0X40,0X31,0X01,0XA3,0X02,0X11,0X08,0X80,0X40,0X6C,0X30,0X04,0X39,0XB0,0X51,
0XB8,0X48,0X01,0X23,0X60,0X00,0X20,0X48,0XE4,0X01,0X00,0X3D,0X07,0X00,0X00,0X00,
0X00,0X00,0X1E,0X05,0X02,0X1F,0X88,0X08,0XD2,0X12,0X01,0XA1,0X82,0XF0,0X67,0XF0,
0X01,0XC4,0X71,0X01,0X20,0X24,0X01,0X82,0X08,0X18,0X82,0X00,0X63,0X74,0X00,0X74,
0X01,0X04,0X1C,0X40,0X03,0X00,0X00,0X00,0X20,0X08,0XE0,0X01,0X8C,0X1F,0XA3,0X00,
0X00,0X00,0X00,0X00,0X3C,0X00,0X40,0X7F,0XA4,0X02,0X04,0X04,0X00,0X61,0X81,0XDA,
0XD2,0X1C,0X00,0X48,0X60,0X58,0XBD,0X02,0X00,0XC1,0X08,0X38,0X80,0X80,0X58,0X10,
0X82,0X38,0X00,0X19,0X1E,0X00,0X13,0X80,0X18,0X20,0X04,0X71,0XE0,0X00,0XB0,0X3F,
0XC7,0X80,0X00,0X00,0X00,0X00,0X7C,0X98,0X00,0XFF,0X08,0X10,0X08,0X06,0X00,0X01,
0X08,0XE8,0XE5,0XC7,0X80,0X0E,0X31,0X00,0X38,0X00,0X80,0X64,0X82,0XF8,0X80,0X00,
0XC4,0X30,0X0C,0X20,0X44,0X55,0X1E,0X00,0X09,0X80,0X40,0X00,0XC0,0X8B,0XE0,0X00,
0XC0,0X1F,0XE1,0XC0,0X00,0X00,0X00,0X00,0X70,0X00,0X27,0XE7,0X00,0X00,0X00,0X01,
0X00,0X80,0XA8,0XF9,0XC3,0X85,0XA0,0X00,0X78,0X42,0X30,0X80,0X80,0X30,0X40,0X1D,
0X80,0X00,0XD0,0X31,0X00,0X70,0X00,0X00,0X0C,0X00,0X01,0X50,0X00,0X08,0X28,0X01,
0XE0,0X00,0XD1,0X1C,0XF4,0XE0,0X00,0X00,0X00,0X00,0X60,0X02,0X3F,0XCF,0X00,0X02,
0X28,0X20,0X00,0X11,0X80,0XE3,0XE0,0X09,0XFC,0X00,0XB2,0X01,0X38,0X00,0X81,0X18,
0X40,0XCB,0X80,0XC8,0XC2,0X39,0X11,0X78,0X84,0X80,0X06,0X02,0X01,0X80,0X04,0X00,
0X40,0X01,0XB0,0X01,0X64,0X5C,0X7D,0X70,0X00,0X00,0X00,0X00,0X40,0X00,0X3F,0X8F,
0X04,0X00,0X00,0X02,0X50,0X81,0X80,0XEB,0X84,0X28,0X3F,0X00,0X18,0X00,0X38,0X90,
0X00,0X1C,0X20,0X4A,0X80,0X00,0XC9,0XB0,0X00,0X60,0X80,0X04,0X24,0X04,0X21,0X02,
0X42,0X00,0X40,0X01,0XB1,0X00,0X6B,0X1E,0X3C,0X38,0X00,0X00,0X00,0X00,0X00,0X10,
0X7C,0X0F,0X01,0X00,0X04,0X84,0X50,0X29,0X24,0XE3,0XAA,0X10,0X1B,0X80,0X18,0X00,
0X3D,0X00,0X09,0X44,0X10,0X88,0X82,0X07,0X8C,0X30,0X00,0XF8,0X08,0X00,0X07,0X00,
0X09,0X00,0X04,0X16,0X4C,0X01,0XB0,0X0C,0X6C,0X1C,0X0F,0XFC,0X00,0X00,0X00,0X00,
0X00,0X0E,0XF8,0X0E,0X00,0X09,0X00,0X00,0X40,0X40,0X80,0XC2,0X04,0X40,0X86,0XE2,
0X18,0X00,0X3D,0X00,0X00,0X15,0X88,0X1E,0X80,0X81,0X84,0X10,0X40,0X58,0X18,0X25,
0X17,0X80,0X03,0X04,0X25,0X40,0X00,0X21,0X34,0X10,0X54,0X1C,0X07,0XBE,0X00,0X00,
0X00,0X00,0X10,0X3F,0XE0,0X0E,0X00,0X12,0X09,0X08,0X40,0X08,0X88,0XE4,0X24,0X20,
0X13,0XBC,0X8C,0X80,0X1C,0X00,0X10,0X03,0X0C,0X3E,0X80,0X0B,0X25,0X30,0X08,0X85,
0X7E,0XEB,0XF7,0X02,0X51,0X83,0X08,0X01,0X40,0X09,0X18,0X20,0X74,0X4E,0X01,0XF6,
0X00,0X00,0X00,0X00,0X03,0XFF,0X00,0X1E,0X1A,0X00,0X08,0X00,0X00,0X20,0X99,0XCF,
0X04,0X00,0X10,0XCE,0X0E,0X20,0X3C,0X04,0X00,0X01,0X84,0X5C,0X80,0X21,0XC2,0X31,
0X01,0XF2,0X07,0X94,0X03,0X80,0X13,0X80,0X01,0X00,0X04,0X01,0X08,0X90,0X38,0X0E,
0X00,0XF3,0X80,0X00,0X00,0X00,0X2F,0XF8,0X00,0X1E,0X00,0X22,0X30,0X60,0X00,0X21,
0XD6,0XCC,0X09,0X00,0X00,0X6F,0X0F,0X00,0X38,0X00,0X80,0X00,0XE3,0X2D,0XE0,0X03,
0X80,0XF2,0X0F,0XF2,0X4C,0X50,0XEB,0XA0,0X01,0X8C,0X90,0X04,0X00,0X05,0X10,0X18,
0X1C,0X2E,0X00,0X7D,0X80,0X00,0X00,0X00,0X7F,0X40,0X00,0X1E,0X00,0X18,0X18,0X1A,
0X00,0X03,0XC0,0XDD,0X00,0X82,0X70,0X1F,0XC6,0X14,0X94,0X20,0X40,0X80,0X21,0X48,
0X60,0X23,0X10,0X90,0X3F,0XFD,0XC0,0X06,0X11,0XC0,0X91,0X90,0X00,0X28,0X00,0X11,
0X08,0X00,0X1E,0X16,0X00,0X0F,0XC0,0X00,0X00,0X00,0X10,0X00,0X00,0X1D,0X00,0X10,
0X00,0X42,0X22,0X01,0XA1,0XFC,0X26,0X04,0X10,0X1F,0XF6,0XC0,0X3E,0X46,0X10,0X01,
0X19,0X08,0XC9,0X43,0X40,0X39,0XC9,0X90,0X00,0X00,0X01,0X80,0X41,0X00,0X00,0X00,
0X00,0X01,0X88,0X50,0X0C,0X4E,0X00,0X07,0XE0,0X00,0X00,0X00,0X00,0X00,0X00,0XBC,
0X00,0X00,0X71,0X00,0X00,0X21,0XC1,0XF8,0X10,0X20,0X00,0X07,0XF7,0X00,0XBE,0X00,
0X00,0X00,0X0C,0X18,0X4A,0X46,0X00,0XB8,0X83,0XC2,0X00,0X02,0X01,0XE0,0X01,0XA5,
0X0C,0X44,0X00,0X25,0X84,0X00,0X9E,0X5E,0X00,0X01,0XF8,0X00,0X00,0X00,0X00,0X00,
0X00,0X3C,0X08,0X00,0X40,0X00,0X20,0X01,0X80,0XF7,0X02,0X24,0X00,0X05,0XBF,0X46,
0X1F,0X00,0X02,0XB0,0X06,0X8C,0X50,0X27,0X5F,0XFC,0X63,0X04,0XA0,0X01,0X04,0XC0,
0X41,0X81,0X00,0X00,0X50,0X83,0X90,0X00,0X16,0X06,0X00,0X00,0X7C,0X00,0X00,0X00,
0X00,0X00,0X00,0X7C,0X08,0X88,0X50,0X00,0X20,0X00,0XD0,0XE5,0X03,0X01,0X00,0X27,
0XFF,0XC0,0X9F,0X00,0X01,0X00,0X0B,0X88,0X48,0X86,0X4F,0X70,0X07,0X82,0X00,0X00,
0X22,0XE0,0X01,0X00,0X00,0X00,0XB0,0X01,0XA7,0X00,0X81,0X0E,0X00,0X00,0X1E,0X00,
0X00,0X00,0X00,0X00,0X00,0X38,0X22,0X49,0X82,0X80,0X19,0X04,0X85,0XE2,0X00,0X00,
0X01,0X0A,0XFF,0XA0,0X3F,0XC0,0X50,0X00,0X89,0XC8,0X41,0X0E,0X5F,0XB2,0X56,0X30,
0X20,0X00,0X1C,0X60,0X01,0X02,0X00,0X04,0X02,0X05,0X83,0X03,0X07,0X0E,0X00,0X00,
0X07,0XC0,0X00,0X00,0X00,0X00,0X00,0X78,0X08,0X18,0X08,0X00,0X14,0X2C,0XC1,0XC1,
0XE0,0X00,0X05,0X02,0X1F,0XC0,0X9F,0X2A,0X00,0X09,0X00,0X6C,0X40,0X4F,0XF1,0X90,
0X04,0X08,0X80,0X02,0X04,0XE0,0X81,0X10,0X00,0X00,0X00,0X01,0XF2,0X10,0X03,0X27,
0X00,0X00,0X41,0XE0,0X00,0X00,0X00,0X00,0X00,0X78,0X10,0X08,0X00,0X80,0X20,0X01,
0X81,0XCD,0X18,0X08,0X00,0X03,0X37,0XE0,0X3F,0X80,0X09,0X00,0X00,0X7C,0X00,0X4F,
0X00,0X31,0X06,0X00,0X00,0X00,0X21,0X38,0X01,0X12,0X00,0X80,0X00,0X06,0X41,0X41,
0X01,0X17,0X00,0X00,0X00,0X18,0X00,0X00,0X00,0X00,0X00,0XF8,0X00,0X0C,0X00,0X20,
0X02,0X85,0XC8,0XC4,0X45,0X40,0X00,0X24,0X0F,0XF8,0X1D,0X99,0X80,0X02,0X20,0X5E,
0XE4,0X7C,0X0A,0X52,0X5D,0X02,0X80,0X00,0X80,0X70,0X01,0X42,0X90,0X04,0X00,0X00,
0X43,0X04,0X02,0XA7,0X00,0X00,0X00,0X06,0X00,0X00,0X00,0X00,0X00,0XF0,0X00,0X09,
0X00,0X00,0X00,0X25,0XC0,0XE2,0X04,0X00,0X08,0X01,0X49,0XEE,0X1F,0XE0,0X04,0X02,
0X20,0X0B,0X21,0XFC,0X22,0X19,0X1C,0X44,0X00,0X00,0X00,0X78,0X09,0X50,0X40,0X10,
0X04,0X04,0X61,0X88,0X01,0X83,0X00,0X00,0X00,0X00,0X00,0X00,0X00,0X00,0X00,0X73,
0XA2,0XC9,0X60,0X5C,0X02,0X01,0XC1,0XC4,0XC4,0X00,0X02,0X13,0X40,0XD7,0X9D,0XE4,
0X88,0X13,0X00,0X07,0X6F,0X08,0XD0,0X18,0X0A,0X0C,0X40,0X00,0X00,0X38,0X11,0X00,
0X20,0X00,0X01,0X02,0X20,0XC0,0X01,0XC3,0X00,0X00,0X00,0X00,0X00,0X00,0X00,0X00,
0X00,0XF0,0X80,0X2C,0X60,0X0A,0X04,0X00,0XE9,0XC0,0X04,0X01,0X00,0X00,0X03,0X31,
0X5E,0XC0,0X02,0X09,0X16,0X55,0XAE,0X09,0X40,0X08,0X18,0X10,0X00,0X40,0X21,0X34,
0X90,0X42,0X00,0X40,0X00,0X80,0X00,0X40,0XE0,0XC7,0X00,0X00,0X00,0X00,0X00,0X00,
0X00,0X00,0X00,0XF0,0X02,0X6C,0X00,0X82,0X40,0X80,0XD5,0XD4,0X08,0X00,0X00,0X04,
0X64,0X70,0X9C,0X60,0X20,0X08,0X80,0X03,0X78,0X58,0X02,0X18,0X10,0X20,0X00,0X00,
0X02,0X38,0X40,0X26,0X44,0X32,0X80,0X04,0X31,0X40,0X04,0XC3,0X80,0X00,0X00,0X00,
0X00,0X00,0X00,0X00,0X00,0XE0,0X10,0X04,0X80,0X20,0X64,0X00,0XC1,0XC0,0X00,0X00,
0X77,0XFF,0X8A,0X38,0X9D,0XE0,0X1A,0X00,0X60,0X61,0XE0,0X93,0X08,0X38,0X70,0XA2,
0X04,0X00,0X24,0X78,0X32,0X44,0X06,0X09,0X40,0X11,0X30,0X41,0X00,0XC3,0X00,0X00,
0X00,0X00,0X00,0X00,0X00,0X00,0X01,0XE4,0X44,0X0C,0X00,0X00,0X00,0X80,0XC1,0XC2,
0X40,0XFF,0XFF,0XFF,0XF8,0X18,0X9E,0X70,0X00,0X14,0X48,0XC0,0XE4,0X33,0X12,0X18,
0X7F,0XFF,0XC0,0X00,0X00,0X76,0X40,0X00,0X01,0X0C,0X01,0X64,0X11,0X20,0X80,0X63,
0X00,0X00,0X00,0X00,0X00,0X00,0X00,0X00,0X01,0XE0,0XB1,0X14,0X00,0X18,0X10,0X00,
0X61,0X80,0X1F,0XF3,0X0F,0XAB,0XFF,0X18,0X4C,0X70,0X00,0X04,0X12,0X44,0XE0,0X18,
0X2F,0XDA,0X68,0X14,0X5F,0X40,0X00,0X3A,0X42,0X00,0X00,0X10,0X03,0X00,0X18,0X20,
0X20,0XE3,0X80,0X00,0X00,0X00,0X00,0X00,0X00,0X00,0X01,0XC4,0X00,0XCC,0X80,0X49,
0X45,0X00,0X61,0XC1,0XDF,0X82,0X2A,0X5B,0X7F,0XBC,0X0C,0X38,0X02,0X01,0X01,0X20,
0X00,0X30,0X80,0X9C,0XC0,0X4F,0X00,0X64,0X00,0X1D,0X20,0X02,0X00,0X11,0X00,0X90,
0XB8,0X30,0X00,0X23,0X80,0X00,0X00,0X00,0X00,0X00,0X00,0X00,0X01,0XD1,0X00,0X2D,
0X82,0X81,0X10,0X40,0XF9,0XC5,0X40,0X04,0X60,0X01,0XFD,0XCC,0X0E,0X3C,0X02,0X08,
0X10,0X43,0X04,0X35,0X04,0X18,0XEF,0X79,0X40,0X80,0X00,0X1B,0X04,0X80,0X01,0X80,
0X01,0XA2,0X84,0X00,0X00,0X7F,0X00,0X00,0X00,0X00,0X00,0X00,0X00,0X00,0X00,0XD8,
0X00,0X04,0X00,0X00,0X00,0X58,0X61,0X14,0X80,0X00,0X02,0X15,0XF1,0XF6,0X06,0X18,
0X10,0X10,0X14,0X64,0X09,0X66,0X02,0X1B,0XBF,0XFF,0XFA,0X25,0XC0,0X0C,0X13,0X02,
0X08,0X00,0X4C,0X40,0X04,0X90,0X01,0X33,0X80,0X00,0X00,0X00,0X00,0X00,0X00,0X00,
0X01,0X80,0X00,0XAC,0X00,0X10,0X4C,0X00,0XE1,0X81,0XA0,0X7F,0X7F,0X40,0X8A,0XB8,
0X2D,0X18,0X00,0XA0,0X00,0X6A,0X89,0X69,0X01,0XFB,0XBF,0X4E,0XFF,0X82,0X44,0X0C,
0X00,0X04,0X40,0X00,0X00,0X20,0X42,0X28,0X20,0X3B,0X80,0X00,0X00,0X00,0X00,0X00,
0X00,0X00,0X03,0XC0,0X00,0X1C,0X00,0X04,0X12,0X00,0XE1,0XC0,0X47,0XFF,0XFF,0XF6,
0X0D,0X1D,0X0C,0X4E,0X00,0X01,0X00,0X60,0X40,0X60,0X0F,0XF9,0XD9,0X7A,0XFF,0XF0,
0X00,0X14,0X80,0X00,0X00,0X00,0X00,0X10,0X03,0X28,0X02,0X1F,0X00,0X00,0X00,0X00,
0X00,0X00,0X00,0X00,0X03,0X85,0X46,0X1E,0X0A,0X00,0X61,0X00,0X70,0X82,0X07,0XFF,
0XFF,0X5F,0XE4,0X0F,0X84,0X0E,0X01,0X02,0X20,0X68,0X09,0XC8,0X3D,0X6F,0XDC,0XDD,
0XDA,0X9E,0X41,0X06,0X84,0X02,0X48,0X00,0X20,0X50,0X81,0X84,0X01,0X9A,0X80,0X00,
0X00,0X00,0X00,0X00,0X00,0X00,0X07,0X80,0X01,0X7C,0X00,0X40,0X10,0X09,0X31,0XC0,
0X7E,0XFB,0XEB,0X51,0X72,0X85,0X8E,0X2F,0X09,0X01,0X09,0X60,0X10,0XC0,0X7B,0XBF,
0XBF,0XD4,0X1F,0X46,0X8B,0X8E,0X02,0X04,0X08,0X04,0X00,0X02,0X00,0X44,0X00,0X0E,
0X80,0X00,0X00,0X00,0X00,0X00,0X00,0X00,0X07,0X80,0X08,0XBC,0X20,0X00,0X80,0X01,
0X20,0X82,0XFF,0XFF,0XF3,0XFF,0XFD,0X01,0X8E,0X1F,0X00,0X00,0X00,0X6E,0X08,0XD1,
0XEF,0X4F,0XFF,0XCE,0X7F,0X5F,0XE1,0X0F,0X20,0XC0,0X00,0X08,0X0A,0X94,0X00,0X66,
0X00,0X8F,0XC0,0X00,0X00,0X00,0X00,0X00,0X00,0X00,0X0F,0X08,0X00,0X7C,0X10,0X32,
0X05,0X00,0X74,0X81,0XF7,0XFF,0XDD,0XFF,0XFD,0XC1,0XE6,0X07,0X80,0X30,0X00,0XC8,
0X40,0X93,0XDC,0XFF,0X6A,0X1F,0XEF,0XEF,0XFC,0X26,0X12,0X02,0X00,0X02,0X00,0X0B,
0X50,0X32,0X09,0X03,0XC0,0X00,0X00,0X00,0X00,0X00,0X00,0X00,0X0F,0X00,0X42,0XFC,
0X03,0X00,0X00,0X63,0X34,0X87,0XFF,0X7F,0XEE,0X1C,0XDF,0XE6,0XD4,0X07,0X8E,0X01,
0X00,0X62,0X41,0X9F,0X7F,0XFD,0X7E,0X9A,0X1F,0XFF,0XFF,0X86,0X08,0X03,0X04,0X40,
0X01,0X41,0X81,0X3B,0X47,0X03,0XE0,0X00,0X00,0X00,0X00,0X00,0X00,0X00,0X0E,0X07,
0X21,0XE4,0X05,0X04,0X08,0X00,0X31,0X8F,0XFF,0XFF,0XD1,0XBB,0XFF,0XF8,0X4F,0X89,
0XD4,0X80,0X10,0X60,0X09,0XBF,0XFF,0XFB,0X5A,0X3D,0X03,0XFF,0X77,0XF7,0X94,0X00,
0X04,0X80,0X00,0X00,0X68,0X8F,0X80,0X01,0XC0,0X00,0X00,0X00,0X00,0X00,0X00,0X00,
0X0E,0X00,0X03,0XDD,0X2A,0X00,0X11,0X02,0XF1,0XFF,0XDE,0XFD,0XFF,0XDF,0XFF,0XCE,
0X26,0X87,0XC8,0X00,0X08,0X34,0X01,0X6E,0XEF,0XE7,0X48,0XE8,0XD7,0XFF,0X1F,0XDB,
0XA2,0X00,0X08,0X04,0X02,0X00,0X60,0X0D,0XB0,0X00,0X80,0X00,0X00,0X00,0X00,0X00,
0X00,0X00,0X1E,0X00,0X07,0X9E,0X05,0X00,0X60,0X11,0X34,0XFF,0XFF,0XFA,0XD4,0XF9,
0XBF,0XDF,0X36,0X83,0XE0,0X00,0X20,0X60,0X01,0XC7,0X89,0XF6,0X9E,0X4F,0XEF,0XFE,
0XF6,0XFF,0X00,0X00,0X00,0X08,0X10,0X01,0X70,0X07,0XC0,0X00,0XE0,0X00,0X00,0X00,
0X00,0X00,0X00,0X00,0X1E,0X00,0X0F,0X8D,0XA1,0X40,0X00,0X00,0X38,0XFF,0XF0,0X7D,
0XC0,0X93,0XFE,0XFE,0X9E,0X44,0XF0,0X00,0X21,0X60,0X01,0XFE,0X09,0X2E,0X05,0XC5,
0X97,0X77,0XFF,0XFF,0X00,0X81,0X94,0X00,0X00,0X00,0XB8,0X01,0X80,0X80,0XF0,0X00,
0X00,0X00,0X00,0X00,0X00,0X00,0X1C,0X00,0X0F,0X1E,0X13,0X81,0X40,0X00,0X9F,0XFF,
0XE9,0X7C,0X7F,0XA7,0XCF,0XFE,0X87,0X80,0X50,0X10,0X00,0X20,0X03,0XF0,0X17,0X9D,
0X04,0X22,0X1F,0XFB,0XFF,0XFD,0X90,0X00,0X04,0X08,0X22,0X20,0X3C,0X61,0XC0,0X48,
0X70,0X00,0X00,0X00,0X00,0X00,0X00,0X00,0X3D,0X40,0X1E,0X04,0X01,0X04,0X08,0X04,
0X3E,0XFF,0XA2,0XF6,0XE4,0X28,0X7D,0XDF,0XFB,0X00,0XB8,0X00,0X12,0X24,0X11,0XC0,
0X6B,0XB3,0X00,0XCE,0XCD,0X7C,0X7F,0XFF,0X9F,0X40,0X02,0X04,0X41,0X41,0XBE,0X00,
0X61,0X20,0X38,0X00,0X00,0X00,0X00,0X00,0X00,0X00,0X3C,0X00,0X3F,0X8E,0X01,0X80,
0X00,0X02,0XBC,0XFA,0XDA,0X65,0X2C,0X0C,0XBE,0XFD,0XFF,0X82,0X3D,0X42,0X09,0X64,
0X11,0X0D,0X03,0X1E,0X02,0X85,0X23,0X5E,0XBD,0XEE,0X48,0X09,0X00,0X1A,0X80,0X40,
0X33,0X00,0X30,0X00,0X1E,0X00,0X00,0X00,0X00,0X00,0X00,0X00,0X78,0X00,0X3D,0X0E,
0X01,0XA8,0X20,0X01,0X7D,0XE8,0X14,0X6D,0X41,0X67,0X52,0XFF,0XA3,0X84,0XBC,0X01,
0X01,0X72,0X02,0X54,0X43,0XDB,0X09,0X71,0XA1,0X7F,0X27,0XFF,0X04,0X01,0X00,0X20,
0X00,0X06,0X63,0X80,0X18,0X00,0X0E,0X00,0X00,0X00,0X00,0X00,0X00,0X00,0X78,0X02,
0X70,0X3E,0X00,0X90,0X40,0XBF,0XFE,0X6A,0X02,0XFF,0X80,0XFD,0X8E,0XEF,0XC9,0XA9,
0X2C,0X00,0X09,0X60,0X46,0X09,0X07,0XC6,0X89,0X83,0XB7,0X39,0X63,0XF7,0X14,0X10,
0X20,0X02,0X84,0X8A,0X20,0XC1,0X06,0X0B,0X0F,0X00,0X00,0X00,0X00,0X00,0X00,0X00,
0XF0,0X00,0XB0,0X0E,0X50,0XD0,0X92,0X94,0X3E,0X68,0X8C,0XEE,0X00,0XDB,0X1E,0XBF,
0XB0,0XC0,0X7F,0X02,0X00,0X60,0X06,0X22,0X0F,0X8B,0X8C,0X8A,0X84,0X1C,0X20,0XFF,
0X01,0X08,0X10,0X02,0X01,0X44,0X20,0XE0,0X21,0X00,0X07,0X80,0X00,0X00,0X00,0X00,
0X00,0X00,0XF0,0X01,0XC4,0X16,0X00,0XA8,0X00,0X00,0X36,0X62,0X80,0XF7,0X80,0X67,
0XB6,0XC7,0XFC,0X7E,0X27,0X02,0X80,0X30,0X06,0X03,0X0C,0X50,0X01,0X34,0X38,0XBC,
0X30,0XFF,0X60,0X08,0X00,0X08,0X01,0X8B,0X22,0X71,0X00,0X00,0X93,0XC0,0X00,0X00,
0X00,0X00,0X00,0X00,0XE0,0X0B,0XC2,0X0E,0X88,0XC0,0X05,0X28,0X36,0X78,0X26,0XF2,
0X80,0X6C,0X6F,0X2D,0XBE,0X00,0X0F,0X80,0X20,0X30,0X2D,0X02,0X86,0X91,0X21,0X82,
0XD3,0XFC,0X80,0X7F,0X29,0X04,0X40,0X00,0X0C,0X10,0XE9,0X3C,0X88,0X00,0X01,0XC0,
0X00,0X00,0X00,0X00,0X00,0X01,0XE0,0X07,0XC0,0X06,0X10,0XE1,0X0C,0X00,0X37,0X60,
0X43,0XF3,0X80,0XE3,0X10,0XAE,0X31,0XE0,0X0F,0X98,0X20,0XB8,0X58,0X00,0X8E,0XE1,
0X45,0X44,0X60,0X38,0X00,0X7F,0XA0,0X02,0X04,0X02,0X04,0X00,0XE8,0X4E,0X50,0X02,
0X01,0XF0,0X00,0X00,0X00,0X00,0X00,0X09,0XC0,0X0E,0X40,0X4C,0X00,0XE0,0X19,0X16,
0X3F,0XF0,0X28,0XEA,0X21,0XEC,0XC3,0XCE,0X10,0XA0,0X47,0XF0,0X10,0XF8,0X18,0X80,
0X1E,0X24,0X41,0X42,0X8F,0XEC,0X0C,0XDF,0X10,0X00,0X10,0X80,0X40,0X04,0X40,0X03,
0X82,0X91,0X28,0X78,0X00,0X00,0X00,0X00,0X00,0X01,0XC0,0X0C,0X01,0X4C,0X02,0XD8,
0X00,0X30,0X1F,0X60,0X01,0XFA,0X1F,0X04,0X00,0X7E,0X00,0XA0,0X0C,0X60,0X00,0X3C,
0X30,0X02,0X0E,0X32,0X11,0X92,0X13,0X1D,0X01,0X3F,0XD8,0XA0,0X08,0X08,0X00,0X80,
0X40,0X01,0XE5,0X06,0X00,0X38,0X01,0X00,0X00,0X00,0X00,0X03,0X81,0X18,0X18,0X46,
0X00,0XE0,0X00,0X00,0X1A,0XB0,0X07,0XED,0XDD,0X90,0XE1,0X8E,0X14,0X00,0X02,0XA1,
0X20,0X38,0X20,0X00,0X0E,0X04,0X08,0X20,0X02,0X7C,0X02,0X1F,0X09,0X80,0X20,0X40,
0X02,0X00,0X43,0X00,0X3E,0X04,0X04,0X3C,0X00,0X00,0X00,0X00,0X00,0X03,0X80,0X30,
0X00,0X8E,0X29,0XF0,0X22,0X44,0X1F,0XF1,0X47,0XFC,0X67,0XBD,0XCA,0X0E,0X50,0X00,
0X00,0XF1,0X80,0X38,0X70,0X00,0X1F,0X81,0XD2,0X70,0X0A,0X7F,0X00,0X9B,0X00,0XC0,
0X00,0X02,0X00,0X86,0X40,0X0C,0X1F,0X80,0X00,0X4F,0X00,0X00,0X00,0X00,0X00,0X07,
0X80,0XF0,0X0A,0X06,0X02,0XE6,0X18,0XA0,0X3F,0XFB,0X3D,0XD8,0X00,0XFD,0X81,0XBF,
0X40,0X84,0X41,0XB0,0X84,0X18,0XE1,0X00,0X1C,0X81,0X00,0X6A,0X4B,0X3C,0X92,0X3D,
0X41,0X0A,0X04,0X21,0X08,0X20,0XE1,0X00,0X41,0XEB,0X00,0X07,0XC0,0X00,0X00,0X00,
0X00,0X06,0X00,0XE0,0X49,0X44,0X20,0XE0,0X80,0XA0,0XAF,0XB0,0X05,0XCA,0X85,0X5E,
0XC9,0X17,0X20,0X20,0X00,0X38,0X00,0X1E,0X40,0X00,0X1C,0X80,0X00,0X32,0X49,0X7D,
0X00,0X3E,0X40,0X80,0X70,0X80,0X42,0X41,0XE0,0X40,0X00,0XFC,0X14,0X25,0XE0,0X00,
0X00,0X00,0X00,0X0E,0X01,0X80,0X0D,0X4C,0X04,0XE8,0X00,0X00,0XBD,0XFC,0X49,0XE9,
0X85,0X7B,0X0E,0X0E,0X80,0X40,0X80,0X5F,0XC2,0X9A,0XC0,0X40,0X0F,0X06,0X00,0XCC,
0X02,0XFA,0XD4,0X96,0XF2,0X20,0X08,0X00,0X8A,0X00,0XCC,0X48,0X00,0XBF,0XB0,0X18,
0XFC,0X00,0X80,0X00,0X00,0X0C,0X27,0XD8,0X08,0X24,0X80,0X74,0X00,0X0A,0X28,0XD0,
0X48,0XE4,0X50,0XAF,0X1D,0X6F,0X00,0X00,0X00,0X0E,0XA1,0XBD,0X82,0X00,0X0F,0X18,
0XA3,0X02,0X10,0X34,0X20,0X1F,0X02,0X60,0X08,0X00,0XC0,0X00,0X00,0X40,0X01,0XFF,
0XFB,0X4A,0X3F,0XCF,0X80,0X00,0X00,0X1D,0X0D,0XC0,0XC8,0X3C,0X60,0X71,0X20,0X08,
0X2B,0X94,0X40,0XF8,0X83,0XFE,0X00,0X3A,0X00,0X20,0X84,0X3F,0X00,0X1D,0X80,0X10,
0X08,0X91,0X02,0X05,0X3C,0X7C,0X40,0X3F,0X1A,0X90,0X21,0X00,0X00,0XD4,0X82,0XC0,
0X01,0XC7,0XFF,0XF0,0X07,0XFC,0X00,0X00,0X00,0X18,0X0F,0XC1,0X1C,0X39,0X40,0X70,
0X02,0X84,0X34,0X78,0X42,0X48,0X10,0X6F,0X00,0XFE,0X00,0X50,0X02,0X13,0X03,0X1D,
0X80,0X28,0X0E,0X06,0X20,0X08,0X65,0X7C,0X00,0X3F,0X01,0X02,0X20,0X22,0X00,0X03,
0XB1,0X60,0X48,0XC0,0X7F,0XFF,0XFF,0XC0,0X01,0X00,0X00,0X38,0X3F,0XC0,0X1C,0X48,
0X90,0X38,0X00,0X84,0X99,0XF8,0X00,0X79,0X00,0X7B,0X04,0X1E,0X00,0X00,0X00,0X03,
0XA0,0X1F,0X08,0X00,0X06,0X04,0X61,0X20,0X00,0XFC,0X08,0XBE,0X41,0X00,0X20,0X00,
0X80,0X01,0X84,0X68,0X01,0XC0,0X00,0X49,0XEC,0X00,0X00,0X00,0X00,0X3C,0X79,0XC1,
0X08,0X0C,0X00,0X70,0X02,0X00,0X08,0XE8,0X00,0X7C,0X00,0XBC,0X88,0X04,0X20,0X11,
0X00,0X20,0XC9,0X8E,0X20,0X80,0X07,0X90,0X00,0X28,0X00,0X58,0X00,0X3F,0X00,0X00,
0X00,0X10,0X00,0X0B,0X80,0X20,0X09,0XC0,0X40,0X00,0X00,0X00,0X00,0X00,0X00,0X60,
0XF1,0XC0,0X19,0X08,0X8C,0X3B,0X08,0X91,0X1C,0XF8,0X00,0X76,0X02,0XB8,0X25,0XEE,
0X10,0X00,0X1C,0X01,0XC0,0X1E,0X26,0X50,0X0F,0X10,0X08,0X36,0X80,0X38,0X02,0X3E,
0X30,0X25,0X08,0X00,0X06,0X11,0X30,0X60,0X01,0XC0,0X00,0X00,0X00,0X00,0X00,0X00,
0X00,0XF1,0XE1,0XE0,0X18,0X08,0X01,0X3C,0X01,0X89,0X5C,0X7C,0X00,0X70,0X00,0X3E,
0X69,0XEE,0X04,0X00,0X00,0X02,0X70,0X4E,0X11,0X00,0X07,0XEB,0X10,0X1B,0X01,0X38,
0X00,0X3F,0X10,0X08,0XB0,0X00,0X00,0X41,0X08,0X70,0X01,0XC0,0X00,0X00,0X00,0X00,
0X00,0X00,0X00,0XC3,0XC1,0XD4,0X1E,0X18,0X8E,0X98,0X82,0X04,0X1C,0X58,0X00,0X35,
0XC3,0X60,0X00,0X7E,0X00,0X00,0X20,0X00,0X38,0X0E,0X61,0X00,0X06,0X01,0X08,0X12,
0X10,0X38,0X00,0XBE,0X00,0X00,0X40,0X08,0X22,0X09,0X20,0X20,0X01,0XC0,0X00,0X00,
0X00,0X00,0X00,0X00,0X01,0XDF,0X01,0XE0,0X1C,0X18,0X82,0X98,0XB0,0X08,0X1F,0X7C,
0X00,0X3C,0X01,0X28,0X41,0XBC,0X01,0X02,0X08,0X80,0X1C,0X0E,0X00,0X44,0X07,0XE2,
0X00,0X10,0X03,0X38,0X00,0X7A,0X48,0X0A,0X22,0X51,0X02,0X03,0X04,0X30,0X01,0XC0,
0X00,0X00,0X00,0X00,0X00,0X00,0X01,0X8C,0X00,0XC8,0X9C,0X58,0X0A,0X4C,0X80,0X00,
0X1C,0X7C,0X00,0X3C,0XA5,0X82,0X91,0X5C,0X00,0X02,0X24,0X00,0X3E,0XA6,0X21,0X08,
0X05,0X44,0X46,0X91,0X02,0X38,0X00,0X63,0X00,0X28,0X02,0X54,0X04,0X01,0X00,0X30,
0X00,0XE0,0X00,0X00,0X00,0X00,0X00,0X00,0X07,0XBC,0X01,0XE1,0X3D,0XD8,0X00,0XAE,
0X84,0X01,0X4F,0X28,0X00,0X1E,0X41,0X15,0X02,0XBC,0X00,0X84,0X00,0X50,0X43,0X2C,
0X00,0X20,0X07,0X90,0X26,0X08,0X81,0XF0,0X00,0X76,0X08,0X00,0X14,0X16,0X02,0X83,
0X08,0X1A,0X01,0XE0,0X00,0X00,0X00,0X00,0X00,0X00,0X06,0X60,0X01,0XE0,0X1C,0X18,
0X00,0X06,0XC4,0X00,0X0E,0XFA,0X00,0X1C,0X50,0X0C,0X5E,0XF8,0X00,0X82,0X00,0X10,
0X83,0X06,0X22,0X20,0X07,0X89,0X8A,0X83,0X60,0XF0,0X00,0XEB,0X54,0X0C,0X00,0X20,
0X81,0X42,0X01,0X90,0X00,0XC0,0X00,0X00,0X00,0X00,0X00,0X00,0X1F,0XC0,0X00,0XE0,
0X59,0X10,0X31,0X4F,0XF1,0X84,0X16,0X38,0X00,0X0C,0X88,0X80,0X20,0X1A,0X02,0X00,
0X00,0X02,0X01,0XF2,0X00,0X04,0X03,0X28,0X20,0X08,0X86,0XE0,0X00,0XC2,0X90,0X00,
0X80,0X20,0X22,0X06,0X00,0X5C,0X00,0X60,0X00,0X00,0X00,0X00,0X00,0X00,0X1F,0X80,
0X00,0XF0,0X1C,0X38,0X02,0X97,0XC0,0X00,0X07,0X7C,0X00,0X08,0X08,0X39,0X18,0X10,
0X00,0X01,0X01,0X10,0X05,0X62,0X00,0X00,0X01,0XD2,0X30,0X54,0XF5,0XC0,0X00,0XE6,
0X00,0X80,0X01,0X00,0X20,0X06,0X00,0X08,0X01,0XC0,0X00,0X00,0X00,0X00,0X00,0X00,
0X7F,0X00,0X00,0XF0,0X1C,0X18,0X00,0X97,0XE0,0X24,0X0F,0X0C,0X00,0X01,0X22,0X40,
0X0F,0X10,0X00,0X20,0X10,0X00,0X00,0X3A,0X48,0X30,0X01,0X83,0X40,0X04,0X6C,0X80,
0X00,0XC3,0X92,0X30,0X00,0X40,0X10,0X06,0X00,0X08,0XC0,0XC0,0X00,0X00,0X00,0X00,
0X00,0X00,0X74,0X00,0X00,0XF0,0X98,0X39,0X11,0XC7,0XE0,0X81,0X07,0X1E,0X00,0X00,
0X38,0X94,0X0D,0X90,0X00,0X00,0X02,0X11,0X08,0X1F,0X00,0X00,0X48,0XC0,0X88,0X14,
0X27,0X10,0X01,0X87,0XA0,0X40,0X00,0X40,0X04,0X0C,0X00,0X08,0X21,0XE0,0X00,0X00,
0X00,0X00,0X00,0X00,0X70,0X00,0X00,0XF0,0X1D,0X33,0X80,0X82,0XE0,0X00,0X8B,0X8E,
0X00,0X00,0XF9,0X81,0XC3,0X70,0X00,0X10,0X00,0X00,0X01,0X46,0X40,0X21,0X20,0X66,
0X14,0X14,0X97,0X00,0X01,0X33,0X00,0X62,0X00,0XC0,0X18,0X0C,0X00,0X0C,0X85,0XC0,
0X00,0X00,0X00,0X00,0X00,0X00,0X00,0X00,0X00,0XF0,0X9C,0XB8,0X02,0X84,0XE6,0X60,
0X89,0XC6,0X00,0X03,0XDC,0XB7,0XC6,0X20,0X00,0X02,0X00,0X00,0X28,0X13,0X00,0X50,
0X44,0X28,0X88,0X0E,0X5F,0X00,0X01,0X07,0X05,0X08,0X08,0XC0,0X00,0X0A,0X01,0X0C,
0X10,0XC0,0X00,0X00,0X00,0X00,0X00,0X00,0X40,0X00,0X00,0X70,0X1C,0XB8,0X00,0X85,
0XF1,0X02,0X03,0XE2,0X00,0X00,0XEC,0X16,0X36,0X40,0X04,0X10,0X00,0X40,0X00,0X83,
0X80,0X80,0X0C,0X1E,0X09,0X4B,0X3E,0X04,0X04,0X83,0X08,0X00,0X82,0X40,0X04,0X4B,
0X00,0X04,0X61,0XE0,0X00,0X00,0X00,0X00,0X00,0X00,0X00,0X00,0X00,0X35,0X1C,0X78,
0X10,0XD4,0X72,0X04,0X41,0XF0,0X00,0X00,0X7B,0XEC,0XC0,0XC2,0X00,0X00,0X00,0X10,
0X01,0X80,0X01,0X00,0X07,0XC7,0XCC,0X83,0X3C,0X00,0X04,0X07,0X10,0X20,0X2A,0XC0,
0X20,0X18,0X04,0X0C,0X01,0XE0,0X00,0X00,0X00,0X00,0X00,0X00,0X00,0X00,0X00,0X78,
0X1C,0X78,0X40,0XE4,0X72,0X02,0X07,0XFC,0X00,0X00,0X3C,0X41,0X77,0XC0,0X01,0X00,
0X01,0X00,0X00,0X00,0X20,0X00,0X00,0XF6,0XE0,0XBF,0X70,0X00,0X58,0X1F,0X04,0X10,
0X41,0XD8,0X00,0X30,0X34,0X26,0X00,0XE0,0X00,0X00,0X00,0X00,0X00,0X00,0X00,0X00,
0X00,0X3C,0X18,0X7C,0X00,0XC7,0X78,0X01,0X40,0XF9,0X00,0X00,0X1F,0XA0,0X6E,0X80,
0X01,0X00,0X00,0X00,0X00,0X78,0X01,0X20,0X00,0X2F,0XFB,0XFB,0XDA,0X07,0XF8,0X07,
0X00,0X20,0X01,0X81,0X00,0XB0,0X20,0X0C,0X01,0XE0,0X00,0X00,0X00,0X00,0X00,0X00,
0X00,0X00,0X00,0X38,0X5C,0X78,0X60,0XDC,0X78,0X08,0X0F,0X7C,0X3C,0X00,0X0F,0XEF,
0XFF,0XC0,0X22,0X00,0X00,0X00,0X00,0X05,0X00,0X00,0X00,0X01,0XFE,0XE4,0X00,0X3B,
0XE2,0X17,0X00,0X00,0X01,0X80,0X09,0X30,0X05,0X06,0X00,0XE0,0X00,0X00,0X00,0X00,
0X00,0X00,0X00,0X00,0X00,0X39,0X14,0XF9,0X02,0XD6,0X3C,0X81,0X03,0X78,0X03,0XF8,
0X03,0XFF,0XFF,0XC0,0X08,0X00,0X00,0X00,0X08,0X00,0X00,0X00,0X0C,0X00,0X7F,0X6C,
0X00,0X1F,0X80,0X0F,0X01,0X28,0X02,0X10,0X10,0X68,0X01,0X82,0X20,0X60,0X00,0X00,
0X00,0X00,0X00,0X00,0X00,0X00,0X00,0X38,0X1C,0X78,0X00,0XC3,0X3E,0X00,0X00,0X7C,
0X03,0XFF,0XE0,0XFB,0XF8,0X46,0X02,0X06,0X90,0X00,0X22,0X00,0XC0,0X00,0X01,0X20,
0X83,0XFE,0XAF,0X04,0X68,0X07,0X00,0X00,0X03,0XA4,0X00,0X60,0X4B,0XC7,0X20,0XF0,
0X00,0X00,0X00,0X00,0X00,0X00,0X00,0X00,0X00,0X14,0X18,0X7C,0X00,0XC2,0X3F,0X09,
0X00,0X7C,0X03,0XE4,0XBD,0XFF,0X60,0X00,0X00,0X88,0X20,0X00,0X00,0X90,0X00,0X80,
0X00,0X0C,0X40,0XD1,0X07,0X04,0X06,0X73,0X16,0X00,0X03,0X00,0X10,0XE1,0X40,0X97,
0X02,0X70,0X00,0X00,0X00,0X00,0X00,0X00,0X00,0X00,0X00,0X0D,0X2C,0XFC,0X00,0X43,
0XBD,0X08,0X00,0X1C,0X03,0XFF,0XFF,0X90,0X00,0X00,0X04,0X00,0X00,0X00,0X50,0X00,
0X02,0X10,0X00,0X02,0X00,0X01,0X01,0X00,0X00,0X07,0X00,0X00,0X87,0X1C,0X90,0X46,
0X88,0X43,0X90,0X70,0X00,0X00,0X00,0X00,0X00,0X00,0X00,0X00,0X00,0X1E,0X38,0X7C,
0X20,0XC2,0X3F,0X88,0X01,0X18,0X88,0X6F,0XF8,0X00,0X42,0X80,0X00,0X00,0X00,0X20,
0X20,0X00,0X00,0X00,0X00,0X00,0X28,0X00,0X23,0X10,0X20,0X07,0X00,0X00,0X6F,0X08,
0X98,0XC0,0X01,0X43,0X94,0X70,0X00,0X00,0X00,0X00,0X00,0X00,0X00,0X00,0X00,0X0F,
0X1C,0XFE,0X41,0X42,0X5F,0XC5,0X08,0XBE,0X01,0X00,0X00,0X00,0X00,0X88,0X40,0X40,
0X08,0X02,0X00,0X80,0X00,0X00,0X40,0X00,0X85,0X8C,0X01,0X08,0X00,0X07,0X08,0X00,
0X1E,0X00,0X00,0X8A,0X85,0X20,0XC2,0X78,0X00,0X00,0X00,0X00,0X00,0X00,0X00,0X00,
0X00,0X06,0XBC,0XF6,0X00,0X60,0X8F,0X8C,0X00,0X2E,0X41,0X00,0X81,0X00,0X00,0X00,
0X88,0X00,0X00,0X00,0XC0,0X08,0X20,0X21,0X00,0X00,0X08,0X80,0X01,0X41,0XC4,0X2F,
0X02,0X00,0X1E,0X00,0X01,0X80,0X10,0X30,0XB4,0X78,0X00,0X00,0X00,0X00,0X00,0X00,
0X00,0X00,0X00,0X07,0XF8,0XE4,0X01,0X68,0X0F,0XC3,0X10,0XAE,0X40,0X00,0X40,0X40,
0X00,0X08,0X42,0X04,0X02,0X14,0X20,0X00,0X00,0X00,0X00,0X00,0X00,0X40,0X01,0X02,
0X02,0X0F,0X00,0X00,0X3F,0X00,0X11,0X00,0X90,0X1A,0X01,0X3C,0X00,0X00,0X00,0X00,
0X00,0X00,0X00,0X00,0X00,0X03,0XBD,0XE6,0X10,0X68,0X4F,0XE0,0X20,0X56,0X00,0X44,
0X00,0X00,0X20,0X00,0X00,0X40,0X00,0X20,0X04,0X08,0XA0,0X00,0X00,0X42,0X00,0X00,
0X00,0X01,0X00,0X0F,0X50,0X11,0X3E,0X88,0X03,0X11,0X00,0X0F,0X70,0X38,0X00,0X00,
0X00,0X00,0X00,0X00,0X00,0X00,0X00,0X03,0X9D,0XE4,0X00,0X60,0X0F,0XF0,0X84,0X6E,
0X00,0X00,0X80,0X00,0X02,0X80,0X00,0X00,0X02,0X00,0X03,0X00,0X08,0X02,0X08,0X10,
0X04,0X00,0X69,0X00,0X21,0X03,0X00,0X10,0X7C,0X00,0X03,0X01,0X80,0X13,0X18,0X9C,
0X00,0X00,0X00,0X00,0X00,0X00,0X00,0X00,0X00,0X01,0XFD,0XD6,0X01,0X6A,0X0F,0XF4,
0X24,0X07,0X00,0X15,0X00,0X01,0X8A,0X00,0X04,0X00,0X00,0X04,0X00,0X00,0X00,0X00,
0X00,0X04,0X00,0X00,0X40,0X00,0X00,0X0F,0X80,0XA4,0X7C,0X00,0X1F,0X90,0X40,0X07,
0XF8,0X3C,0X00,0X00,0X00,0X00,0X00,0X00,0X00,0X00,0X00,0X01,0X99,0XC0,0X18,0XA2,
0X0E,0X79,0X84,0X63,0X10,0X00,0X03,0X10,0X18,0X42,0X00,0X00,0X40,0X04,0X00,0X00,
0X00,0X01,0X00,0X18,0X08,0X00,0X00,0X00,0X00,0X4F,0X42,0X11,0XFD,0X08,0X02,0X70,
0X00,0X03,0XF0,0X1E,0X00,0X00,0X00,0X00,0X00,0X00,0X00,0X00,0X00,0X00,0XFD,0XD6,
0X02,0X20,0X06,0X3C,0X00,0X23,0X82,0X00,0X02,0X00,0X02,0X00,0X00,0X00,0X80,0X0E,
0X40,0X00,0X40,0X04,0X40,0X00,0X00,0X02,0X09,0X00,0X01,0X0B,0XDA,0X01,0XFC,0X00,
0XAC,0X01,0X02,0X89,0XFC,0X1C,0X00,0X00,0X00,0X00,0X00,0X00,0X00,0X00,0X00,0X00,
0XED,0XC2,0X02,0XF2,0X0F,0XDF,0X81,0X12,0X81,0X00,0X04,0X08,0X00,0X44,0X00,0X00,
0X00,0X0C,0X06,0X20,0X08,0X10,0X92,0X00,0X00,0X00,0X00,0X82,0X00,0X0F,0X00,0X03,
0XDE,0X02,0X1C,0X88,0X24,0X90,0X78,0X5E,0X00,0X00,0X00,0X00,0X00,0X00,0X00,0X00,
0X00,0X40,0X7F,0XC7,0X20,0X30,0X47,0X3F,0X01,0X1B,0XC0,0X10,0X04,0X00,0X10,0X80,
0X00,0X08,0X10,0X1F,0X00,0X00,0X10,0X00,0X00,0X00,0X00,0X08,0X00,0X0C,0X01,0X1F,
0X82,0X03,0X18,0X01,0X1C,0X28,0X00,0X11,0X7C,0X0E,0X00,0X00,0X00,0X00,0X00,0X00,
0X00,0X00,0X00,0X00,0X3F,0XFE,0X00,0XB0,0X17,0X07,0X40,0X08,0XE1,0X10,0X18,0X80,
0X00,0X00,0X01,0X00,0X00,0X1F,0X42,0X04,0X02,0X20,0X00,0X00,0X00,0X00,0X00,0X48,
0X20,0X0E,0X82,0X27,0XB8,0X20,0X78,0X44,0X18,0XC5,0X3E,0X0E,0X00,0X00,0X00,0X00,
0X00,0X00,0X00,0X00,0X00,0X00,0X1F,0X86,0X03,0XB0,0X4F,0X1B,0XC1,0X0E,0XE0,0X02,
0X00,0X00,0X04,0X31,0X00,0X04,0X00,0X1C,0X00,0X10,0X04,0X04,0X00,0X00,0X04,0X00,
0X02,0X00,0X00,0X4F,0XE2,0X86,0X38,0X00,0X78,0X00,0X00,0X08,0X3D,0X07,0X00,0X00,
0X00,0X00,0X00,0X00,0X00,0X00,0X00,0X00,0X0F,0X87,0X00,0XB0,0X07,0X03,0XE0,0X0E,
0X60,0X00,0X00,0X08,0X01,0X01,0X00,0X20,0X30,0X5C,0X10,0X00,0X00,0X00,0X00,0X00,
0X02,0X12,0X40,0X08,0X00,0X0F,0X80,0X0E,0X30,0X90,0XF0,0X01,0X12,0X58,0XBC,0X07,
0X80,0X00,0X00,0X00,0X00,0X00,0X00,0X00,0X00,0X00,0X07,0X8F,0X60,0X30,0X47,0X00,
0XF0,0X07,0X61,0X20,0X00,0X20,0X01,0X00,0X00,0X00,0X00,0X1C,0X80,0X00,0X10,0X00,
0X40,0X00,0X00,0X00,0X12,0X20,0X04,0X1F,0X80,0X1E,0X78,0XA9,0XE8,0X00,0X00,0X00,
0X7F,0X03,0X80,0X00,0X00,0X00,0X00,0X00,0X00,0X00,0X00,0X00,0X07,0X8F,0X01,0X31,
0X83,0X08,0XF0,0X03,0X31,0X00,0X00,0X09,0X80,0X00,0X40,0X02,0X02,0X19,0X40,0X00,
0X00,0X00,0X00,0X00,0X00,0X00,0X00,0X40,0X30,0X2F,0XC1,0X58,0X20,0X41,0XC0,0X10,
0X0C,0X00,0X3F,0XC7,0X80,0X00,0X00,0X00,0X00,0X00,0X00,0X00,0X00,0X00,0X07,0X1F,
0X82,0X10,0X43,0X80,0XF8,0X05,0XA0,0X02,0X28,0X20,0X00,0X00,0X00,0X05,0X00,0X3C,
0X00,0X00,0X04,0X00,0X00,0X01,0X00,0X78,0X00,0X40,0X00,0X0F,0X94,0X3B,0X60,0X13,
0X84,0X20,0X11,0X00,0X3F,0X93,0X80,0X00,0X00,0X00,0X00,0X00,0X00,0X00,0X00,0X00,
0X07,0X1F,0XC0,0X10,0X03,0X81,0XFC,0X09,0XF0,0X08,0X00,0X00,0X00,0X04,0X00,0X06,
0X00,0X3C,0X02,0X08,0X40,0X00,0X00,0X00,0X20,0X04,0X00,0XA4,0X00,0X0F,0XC0,0X6A,
0X60,0X06,0X80,0X20,0X01,0X00,0X77,0XC1,0XC0,0X00,0X00,0X00,0X00,0X00,0X00,0X00,
0X00,0X00,0X07,0XBE,0X80,0X30,0X02,0X80,0X7F,0X02,0XFE,0X00,0X28,0X00,0X06,0X02,
0X08,0X00,0X00,0X7C,0X30,0X00,0X00,0X00,0X00,0X00,0X01,0X01,0X24,0X00,0X00,0X5F,
0XC0,0XEE,0X30,0X0C,0X08,0X40,0X13,0X10,0X73,0XC1,0XC0,0X00,0X00,0X00,0X00,0X00,
0X00,0X00,0X00,0X00,0X06,0X1F,0X80,0X32,0X01,0X21,0X3F,0X80,0XF8,0X00,0X00,0X00,
0X80,0X00,0X20,0X00,0X10,0XBC,0X01,0X00,0X80,0X00,0X00,0X20,0X00,0X00,0X31,0X20,
0X00,0X1F,0XD0,0XD8,0XE0,0X3C,0X41,0XA4,0X02,0X00,0XE1,0XF0,0XE0,0X00,0X00,0X00,
0X00,0X00,0X00,0X00,0X00,0X00,0X06,0X3F,0X80,0X70,0X12,0XC0,0X7F,0XCF,0X70,0X00,
0X0A,0X08,0X80,0X00,0X00,0X01,0X00,0X38,0X02,0X00,0X00,0X00,0X10,0X00,0X80,0X00,
0X00,0X00,0X00,0X8F,0XC1,0XC4,0X80,0X72,0X10,0X00,0X04,0X08,0XE0,0XF0,0X60,0X00,
0X00,0X00,0X00,0X00,0X00,0X00,0X00,0X00,0X0E,0X39,0X80,0X3F,0X01,0XF9,0X7F,0XA0,
0XFC,0X01,0X00,0X86,0X20,0X01,0X18,0X00,0X00,0X38,0X00,0X00,0X18,0X02,0X00,0X00,
0X82,0X10,0X10,0X20,0X00,0X1D,0XE3,0X85,0XC0,0XE9,0X90,0X0A,0X44,0X20,0X60,0XF8,
0X60,0X00,0X00,0X00,0X00,0X00,0X00,0X00,0X00,0X00,0X0E,0X73,0X80,0X38,0X00,0X6C,
0X3F,0XF2,0X3C,0XC4,0X00,0X00,0X00,0X20,0X00,0X00,0X10,0X38,0X00,0X18,0X00,0X00,
0X01,0X00,0X00,0X10,0X20,0X00,0X00,0X5C,0XC3,0X18,0XC0,0XC4,0X09,0X09,0X06,0X60,
0XE0,0X3E,0X78,0X00,0X00,0X00,0X00,0X00,0X00,0X00,0X00,0X00,0X0E,0X73,0X80,0X62,
0X00,0X64,0XBF,0XFD,0X9E,0X00,0X40,0X00,0X00,0X00,0X00,0X20,0X00,0X10,0X00,0X00,
0X00,0X10,0X04,0X00,0X00,0X1C,0X04,0X02,0X00,0X1C,0XE7,0X08,0X90,0XD0,0X40,0X80,
0X0D,0X40,0XE0,0X1F,0X38,0X00,0X00,0X00,0X00,0X00,0X00,0X00,0X00,0X00,0X1E,0X63,
0X80,0X10,0X00,0X37,0X0F,0XDC,0X1B,0XA0,0X09,0X00,0X08,0X54,0X08,0X00,0X00,0X00,
0X00,0X00,0X00,0X40,0X02,0X84,0X00,0X00,0X10,0X04,0X00,0X1B,0XE6,0X85,0X99,0X00,
0XB9,0X00,0X3B,0X01,0XC0,0X0F,0X1C,0X00,0X00,0X00,0X00,0X00,0X00,0X00,0X00,0X00,
0X1C,0X61,0XC0,0X30,0X01,0X10,0X07,0XFF,0X57,0X00,0X00,0X20,0X14,0X00,0X00,0X00,
0X21,0X00,0XA5,0X50,0X00,0X00,0X00,0X00,0X01,0X01,0X08,0X00,0X00,0X18,0XED,0X21,
0X81,0X48,0X12,0X82,0X90,0X00,0XC0,0X07,0XDC,0X00,0X00,0X00,0X00,0X00,0X00,0X00,
0X00,0X00,0X3C,0XC3,0XE1,0X10,0X80,0X19,0X8F,0XFF,0X87,0X0A,0X20,0X2A,0X42,0X00,
0X80,0X00,0X02,0X80,0X00,0X00,0X00,0X00,0X00,0X02,0X00,0X00,0X00,0X04,0XA0,0X19,
0XDA,0X01,0X22,0X80,0XA0,0X01,0X34,0X11,0X80,0X01,0XEE,0X20,0X00,0X00,0X00,0X00,
0X00,0X00,0X00,0X00,0X2D,0XC1,0XD5,0X10,0X01,0X08,0X01,0XFF,0XC9,0X02,0X00,0X80,
0X48,0X00,0X22,0X00,0X00,0X80,0X00,0X00,0X00,0X01,0X00,0X44,0X04,0X00,0X12,0X02,
0X00,0X1F,0XF0,0X03,0X00,0X80,0X70,0X00,0X70,0X03,0X80,0X00,0XEE,0X00,0X00,0X00,
0X00,0X00,0X00,0X00,0X00,0X00,0X39,0X81,0XE2,0X1A,0X54,0XCE,0XC6,0XF0,0XC3,0XA0,
0X08,0X04,0X90,0X30,0X00,0X20,0X00,0X04,0X00,0X00,0X80,0X00,0X00,0X00,0X00,0X00,
0X00,0X08,0X0D,0X1F,0XF8,0X13,0X00,0X10,0XF2,0X40,0X70,0X27,0X00,0X00,0X3F,0X80,
0X00,0X00,0X00,0X00,0X00,0X00,0X00,0X00,0X3F,0X81,0XC0,0X00,0X04,0X06,0X0E,0XF8,
0X79,0XC0,0X40,0X02,0X00,0X02,0X00,0X00,0X01,0X00,0X00,0X22,0X00,0X14,0X00,0X00,
0X00,0X00,0X02,0X05,0X00,0X18,0XF0,0X06,0X20,0X40,0X30,0X04,0XE2,0X03,0X00,0X00,
0X07,0XE0,0X00,0X00,0X00,0X00,0X00,0X00,0X00,0X00,0X77,0X01,0XE0,0X38,0X09,0X33,
0XC3,0XF8,0X2F,0XC4,0X80,0X00,0X00,0X40,0X00,0X00,0X00,0X10,0X20,0X00,0X08,0X08,
0X00,0X00,0X82,0X80,0X02,0X00,0X00,0X3F,0XF8,0X86,0X08,0X14,0X18,0X50,0XE4,0X07,
0X00,0X00,0X03,0XE0,0X00,0X00,0X00,0X00,0X00,0X00,0X00,0X00,0X67,0X00,0XC0,0X14,
0X00,0X04,0XC2,0X7C,0X01,0XE0,0XC0,0X0A,0X00,0X09,0X40,0X02,0X00,0X00,0X01,0X00,
0X00,0X08,0X10,0X80,0X10,0X00,0X40,0X00,0X20,0XBB,0XE2,0X2C,0X0A,0X20,0X18,0X21,
0XE1,0X0E,0X40,0X00,0X00,0XF8,0X00,0X00,0X00,0X00,0X00,0X00,0X00,0X04,0XEE,0X01,
0XE0,0X18,0X02,0X20,0XE4,0X3C,0X44,0X7C,0X10,0X41,0X00,0X00,0X05,0X00,0X00,0X00,
0X00,0X22,0X00,0X00,0X00,0X00,0X00,0X18,0X00,0X30,0X02,0X3D,0XD2,0X08,0X4D,0X23,
0X18,0X21,0XC0,0X1E,0X00,0X00,0X00,0X38,0X00,0X00,0X00,0X00,0X00,0X00,0X00,0X00,
0XFC,0X00,0XE0,0X50,0X40,0X18,0XF8,0X1C,0X50,0X0D,0X80,0X20,0X24,0X00,0X00,0X00,
0X00,0X00,0X00,0X00,0X00,0X00,0X00,0X00,0X00,0X50,0X40,0X00,0X01,0X3B,0X21,0X6C,
0X02,0X31,0X5C,0X23,0XC9,0X1C,0X00,0X00,0X00,0X00,0X00,0X00,0X00,0X00,0X00,0X00,
0X00,0X00,0XF8,0X00,0XE0,0X14,0X00,0X3C,0X0C,0X1E,0X00,0X03,0X04,0X80,0X0C,0X01,
0X10,0X48,0X02,0X00,0X20,0X40,0X01,0X00,0X80,0X48,0X00,0X04,0X02,0X40,0X04,0X73,
0X80,0XD8,0X10,0X20,0X5D,0X21,0XC0,0X38,0X00,0X00,0X00,0X00,0X00,0X00,0X00,0X00,
0X00,0X00,0X00,0X01,0XF0,0X00,0XE2,0X30,0X28,0X30,0X8F,0X0F,0X10,0X00,0X80,0X00,
0X00,0X00,0X03,0X00,0X00,0X02,0X04,0X04,0X00,0X08,0X00,0X00,0X40,0X01,0X04,0X08,
0X01,0X7F,0XC0,0X38,0X20,0X34,0X9E,0X43,0X80,0X38,0X00,0X00,0X00,0X00,0X00,0X00,
0X00,0X00,0X00,0X00,0X00,0X01,0XE0,0X00,0XF2,0X12,0X01,0X30,0X03,0XAF,0X90,0X10,
0XC0,0X24,0X21,0X00,0X00,0X00,0X80,0X00,0X40,0X00,0X00,0X00,0X10,0X00,0X00,0X08,
0X81,0X00,0X55,0XFE,0X20,0X20,0X40,0X61,0X9E,0X47,0XD0,0X70,0X00,0X00,0X00,0X00,
0X00,0X00,0X00,0X00,0X00,0X00,0X00,0X01,0XC1,0X00,0X70,0X00,0X2A,0X3C,0X90,0X77,
0X00,0X10,0X80,0X00,0X04,0X0A,0X15,0X00,0X04,0X00,0X00,0X00,0X00,0X00,0X00,0X11,
0X04,0X00,0X18,0X80,0X89,0XFE,0X21,0X64,0X41,0X6A,0X1C,0X17,0X90,0X70,0X00,0X00,
0X00,0X00,0X00,0X00,0X00,0X00,0X00,0X00,0X00,0X03,0XC0,0X00,0XF0,0X12,0X02,0X2C,
0X14,0X3B,0X80,0X00,0X00,0X00,0X00,0X00,0X00,0X01,0X04,0X00,0X00,0X00,0X00,0X00,
0X00,0X40,0X00,0X20,0X00,0X20,0X09,0XEE,0X08,0X40,0X40,0X34,0X0C,0X47,0X90,0XE0,
0X00,0X00,0X00,0X00,0X00,0X00,0X00,0X00,0X00,0X00,0X00,0X07,0X80,0X00,0XE0,0X31,
0X08,0XC4,0X22,0X01,0X40,0X01,0X00,0X20,0X00,0X00,0X00,0X00,0X04,0X08,0X00,0X00,
0X10,0X80,0X14,0X20,0X00,0X00,0X00,0X00,0X03,0XFC,0X81,0X40,0XC1,0X78,0X3C,0X0F,
0X03,0XC0,0X00,0X00,0X00,0X00,0X00,0X00,0X00,0X00,0X00,0X00,0X00,0X0E,0X00,0X00,
0X70,0X51,0XC3,0X64,0X00,0X10,0XC0,0X00,0X01,0X00,0X01,0X00,0X04,0X40,0X10,0X08,
0X02,0X00,0X00,0X00,0X00,0X04,0X01,0X00,0X04,0X10,0XA7,0XF8,0X19,0XC0,0X88,0XF0,
0X1C,0X8D,0X83,0X80,0X00,0X00,0X00,0X00,0X00,0X00,0X00,0X00,0X00,0X00,0X00,0X04,
0X00,0X00,0X71,0X00,0X00,0X56,0X61,0X01,0XD0,0X80,0X20,0X00,0X80,0X00,0X00,0X00,
0X00,0X80,0X80,0X00,0X00,0X00,0X00,0X00,0X00,0X18,0X00,0X00,0X25,0XC9,0X89,0X90,
0XA0,0XF1,0X9E,0X9D,0X07,0X00,0X00,0X00,0X00,0X00,0X00,0X00,0X00,0X00,0X00,0X00,
0X00,0X1C,0X00,0X00,0X61,0X05,0X40,0XC6,0X10,0X00,0XF0,0X10,0X00,0X01,0X00,0X20,
0X04,0X00,0X08,0X08,0X04,0X00,0X04,0X22,0X00,0X01,0X10,0X01,0X00,0X00,0X4F,0XCC,
0X8B,0X01,0X09,0XF4,0X1F,0X3D,0X9E,0X00,0X00,0X00,0X00,0X00,0X00,0X00,0X00,0X00,
0X00,0X00,0X00,0X10,0X00,0X00,0X70,0X4C,0X01,0X83,0X03,0X20,0X70,0X00,0X08,0X00,
0X00,0X04,0X04,0X00,0X02,0X00,0X20,0X00,0X01,0X40,0X00,0X00,0X00,0X00,0X00,0X00,
0X3F,0X98,0X23,0X00,0X81,0XF2,0X4D,0X32,0X9C,0X00,0X00,0X00,0X00,0X00,0X00,0X00,
0X00,0X00,0X00,0X00,0X00,0X20,0X00,0X00,0X70,0X20,0X00,0X97,0X20,0X00,0X78,0X08,
0X00,0X01,0X00,0X00,0X40,0X00,0XD3,0X10,0X40,0X40,0X00,0X18,0X0C,0X00,0X00,0X08,
0X00,0X12,0X7F,0XD8,0X0E,0X00,0XE1,0XF9,0X0C,0X72,0X38,0X00,0X00,0X00,0X00,0X00,
0X00,0X00,0X00,0X00,0X00,0X00,0X00,0X00,0X00,0X00,0X7A,0X20,0X01,0X0F,0X00,0X02,
0X38,0X00,0X20,0X00,0X00,0X00,0X00,0X00,0X10,0X01,0X00,0X00,0X20,0X80,0X00,0X20,
0X00,0X20,0X00,0X00,0XBF,0XD8,0X86,0X80,0XC3,0XB9,0X4C,0X70,0XE0,0X00,0X00,0X00,
0X00,0X00,0X00,0X00,0X00,0X00,0X00,0X00,0X00,0X00,0X00,0X00,0X78,0X90,0X02,0X0F,
0X02,0X10,0X3E,0X00,0X00,0X00,0X10,0X20,0X10,0X04,0X40,0X00,0X00,0X20,0X00,0X00,
0X80,0X10,0X00,0X00,0X21,0X0B,0X7B,0X9C,0XDC,0X20,0X13,0XBE,0X4C,0X61,0XE8,0X00,
0X00,0X00,0X00,0X00,0X00,0X00,0X00,0X00,0X00,0X00,0X00,0X00,0X00,0X00,0X38,0X30,
0X16,0X1F,0X00,0X28,0X1E,0X00,0X00,0X00,0X80,0X00,0X00,0X10,0X04,0X00,0X00,0X00,
0X20,0X45,0X80,0X00,0X04,0X00,0X02,0X01,0XF9,0X98,0XFC,0X08,0X03,0X9C,0X1C,0XE7,
0X80,0X00,0X00,0X00,0X00,0X00,0X00,0X00,0X00,0X00,0X00,0X00,0X00,0X00,0X00,0X00,
0X78,0X00,0X06,0X0F,0X80,0X04,0X1C,0X00,0X00,0X80,0X00,0X08,0X01,0X00,0X00,0X08,
0X40,0X08,0X00,0X81,0X80,0X00,0X00,0X00,0X90,0X03,0XF3,0X9A,0XB8,0X40,0X03,0X3C,
0X0D,0XCE,0X00,0X00,0X00,0X00,0X00,0X00,0X00,0X00,0X00,0X00,0X00,0X00,0X00,0X00,
0X00,0X00,0X3A,0X80,0X0E,0X2F,0X8C,0X41,0X0E,0X00,0X80,0X01,0X40,0X00,0X20,0X40,
0X00,0X81,0X20,0X08,0X00,0X03,0X04,0X00,0X20,0X02,0X01,0X07,0XE8,0X98,0X31,0X00,
0X0F,0X1E,0X0F,0XFC,0X00,0X00,0X00,0X00,0X00,0X00,0X00,0X00,0X00,0X00,0X00,0X00,
0X00,0X00,0X00,0X00,0X30,0X10,0X0C,0X07,0X80,0X82,0X07,0X80,0X00,0X00,0X00,0X04,
0X00,0X00,0X00,0X10,0X00,0X00,0X00,0X7F,0X00,0X00,0X90,0X00,0X60,0X1F,0XC1,0X98,
0X22,0XC3,0X0E,0X1E,0X0F,0XF0,0X00,0X00,0X00,0X00,0X00,0X00,0X00,0X00,0X00,0X00,
0X00,0X00,0X00,0X00,0X00,0X00,0X30,0X90,0X1C,0X27,0XC0,0X86,0X17,0X05,0X50,0X00,
0X00,0X00,0X00,0X02,0X06,0X00,0X00,0X00,0X11,0XFF,0X00,0X00,0X00,0X20,0X00,0X1F,
0XC0,0X99,0X70,0X80,0X0E,0X1E,0X0B,0XE0,0X00,0X00,0X00,0X00,0X00,0X00,0X00,0X00,
0X00,0X00,0X00,0X00,0X00,0X00,0X00,0X00,0X60,0X04,0X98,0X06,0XC4,0X00,0XA3,0X00,
0X00,0X00,0X04,0X00,0X00,0X03,0X00,0X00,0X40,0X00,0X03,0XDC,0X00,0X00,0X00,0X04,
0X00,0X9F,0X18,0X3E,0XC4,0X91,0X0E,0X0E,0X1F,0XC0,0X00,0X00,0X00,0X00,0X00,0X00,
0X00,0X00,0X00,0X00,0X00,0X00,0X00,0X00,0X00,0X00,0X79,0X80,0X38,0XC7,0XC5,0X26,
0X87,0X82,0X00,0X30,0X00,0X02,0X00,0X07,0X80,0X00,0X80,0X10,0X04,0XE1,0X00,0X00,
0X04,0X00,0X00,0XFE,0X60,0XD8,0XC1,0X54,0X1E,0X0D,0X1F,0X80,0X00,0X00,0X00,0X00,
0X00,0X00,0X00,0X00,0X00,0X00,0X00,0X00,0X00,0X00,0X00,0X00,0X30,0X01,0X70,0X43,
0XE0,0X00,0X4B,0XC0,0X01,0X00,0X00,0X00,0X00,0X03,0XE0,0XA0,0X00,0X40,0XD3,0X80,
0X40,0X01,0X08,0X00,0X01,0XFF,0X05,0X9B,0X82,0X00,0X1C,0X07,0X3F,0X80,0X00,0X00,
0X00,0X00,0X00,0X00,0X00,0X00,0X00,0X00,0X00,0X00,0X00,0X00,0X00,0X00,0X60,0X80,
0X70,0X0F,0XC0,0X21,0X05,0XC0,0X04,0X00,0X01,0X00,0X44,0X03,0XFA,0XC0,0X04,0X27,
0X7F,0X82,0X00,0X00,0X04,0X82,0X89,0XE8,0X20,0XDB,0X82,0X01,0XDC,0X0F,0X27,0X00,
0X00,0X00,0X00,0X00,0X00,0X00,0X00,0X00,0X00,0X00,0X00,0X00,0X00,0X00,0X00,0X00,
0X3A,0X81,0X70,0X13,0X4C,0X80,0X12,0XE0,0X01,0X00,0X00,0X00,0X00,0X00,0X1F,0XF8,
0X00,0X0B,0XB0,0X00,0X00,0X00,0X00,0X60,0X17,0X70,0X09,0X3B,0X04,0X00,0X38,0X1F,
0XAE,0X00,0X00,0X00,0X00,0X00,0X00,0X00,0X00,0X00,0X00,0X00,0X00,0X00,0X00,0X00,
0X00,0X00,0X30,0X80,0XE0,0X8B,0X6B,0X28,0X01,0X78,0X00,0X82,0X00,0X00,0X00,0X00,
0X13,0XFF,0XA3,0X3D,0X00,0X00,0X00,0X00,0X00,0X00,0X07,0XF0,0X00,0XB6,0X49,0X82,
0X78,0X0F,0X86,0X00,0X00,0X00,0X00,0X00,0X00,0X00,0X00,0X00,0X00,0X00,0X00,0X00,
0X00,0X00,0X00,0X00,0X79,0X11,0XE2,0X03,0XF0,0X01,0X80,0X7C,0X00,0X30,0X20,0X0A,
0X00,0X00,0X40,0X49,0XEE,0XA0,0X00,0X02,0X02,0X01,0X00,0X00,0X2F,0XC1,0X00,0X74,
0X99,0X00,0X30,0X0F,0X8F,0X00,0X00,0X00,0X00,0X00,0X00,0X00,0X00,0X00,0X00,0X00,
0X00,0X00,0X00,0X00,0X00,0X00,0X30,0X05,0XC4,0X03,0X24,0X13,0X98,0X3C,0X00,0X41,
0X00,0X00,0X00,0X00,0X20,0X20,0X80,0X00,0X00,0X00,0X02,0X00,0X80,0X00,0X1F,0X80,
0XA5,0X7F,0X11,0X00,0X70,0X1F,0X84,0X00,0X00,0X00,0X00,0X00,0X00,0X00,0X00,0X00,
0X00,0X00,0X00,0X00,0X00,0X00,0X00,0X00,0X78,0X01,0XE0,0X42,0XF0,0X40,0X85,0X1F,
0X00,0X00,0X00,0X04,0X08,0X00,0X00,0X00,0X00,0X00,0X00,0X00,0X02,0X20,0X00,0X00,
0X7F,0X04,0X00,0XFA,0X20,0X00,0XE0,0X1C,0XEC,0X00,0X00,0X00,0X00,0X00,0X00,0X00,
0X00,0X00,0X00,0X00,0X00,0X00,0X00,0X00,0X00,0X00,0X70,0XC7,0X40,0X03,0XF0,0X80,
0X14,0X0E,0X00,0X00,0X02,0X00,0X20,0X00,0X00,0X00,0X00,0X40,0X20,0X00,0X00,0X10,
0X01,0X00,0XFE,0XC0,0X32,0XF1,0XE0,0X10,0XF0,0X3C,0XE4,0X00,0X00,0X00,0X00,0X00,
0X00,0X00,0X00,0X00,0X00,0X00,0X00,0X00,0X00,0X00,0X00,0X00,0X72,0X07,0XC0,0X05,
0XD4,0X11,0X00,0XA3,0XC0,0X00,0X00,0X00,0X48,0X08,0X00,0X02,0X04,0X00,0X00,0X02,
0X01,0X00,0X80,0X03,0XF8,0X13,0X00,0X73,0X0D,0X80,0XE0,0X3C,0X66,0X00,0X00,0X00,
0X00,0X00,0X00,0X00,0X00,0X00,0X00,0X00,0X00,0X00,0X00,0X00,0X00,0X00,0X60,0X87,
0XC0,0X11,0X98,0X20,0X81,0X87,0XE0,0X00,0X00,0X00,0X00,0X01,0X00,0X00,0X00,0X0A,
0X00,0X00,0X02,0X10,0X00,0X0F,0XF6,0X40,0X01,0X67,0X80,0X01,0XC0,0X38,0X7C,0X00,
0X00,0X00,0X00,0X00,0X00,0X00,0X00,0X00,0X00,0X00,0X00,0X00,0X00,0X00,0X00,0X00,
0XE0,0X4F,0XE4,0X53,0XDD,0X90,0X4C,0X10,0XB8,0X00,0X80,0X10,0X41,0X00,0X00,0X00,
0X00,0X00,0X00,0X00,0X00,0X00,0X00,0X1F,0X87,0X00,0X20,0XC3,0X20,0X09,0XC0,0X38,
0X3C,0X00,0X00,0X00,0X00,0X00,0X00,0X00,0X00,0X00,0X00,0X00,0X00,0X00,0X00,0X00,
0X00,0X00,0X60,0X5C,0XC4,0X43,0XDE,0X40,0X26,0XEC,0X3C,0X20,0X00,0X00,0X00,0X00,
0X00,0X01,0X00,0X00,0X00,0X10,0X02,0X01,0X04,0X5F,0XA0,0X49,0X00,0X86,0X03,0X01,
0XC0,0X70,0X3C,0X00,0X00,0X00,0X00,0X00,0X00,0X00,0X00,0X00,0X00,0X00,0X00,0X00,
0X00,0X00,0X00,0X00,0X60,0X3C,0XF4,0X11,0XCE,0X08,0X01,0X48,0X3C,0X00,0X00,0X00,
0X00,0X00,0X00,0X20,0X10,0X00,0X40,0X80,0X00,0X0A,0X00,0X7E,0X04,0X80,0X01,0X46,
0X80,0X43,0XC0,0XE0,0X1E,0X00,0X00,0X00,0X00,0X00,0X00,0X00,0X00,0X00,0X00,0X00,
0X00,0X00,0X00,0X00,0X00,0X00,0X69,0X78,0XE1,0X45,0XCE,0X03,0X00,0X93,0X8F,0X10,
0X80,0X00,0X00,0X00,0X00,0X00,0X00,0X00,0X00,0X00,0X41,0X08,0X81,0XFD,0X96,0X48,
0X00,0X4C,0X78,0X43,0X80,0XE0,0X0E,0X00,0X00,0X00,0X00,0X00,0X00,0X00,0X00,0X00,
0X00,0X00,0X00,0X00,0X00,0X00,0X00,0X00,0XE0,0X78,0X72,0X09,0XEE,0X80,0X00,0X41,
0X1B,0XE2,0X00,0X01,0X00,0X40,0X01,0X10,0X50,0X00,0X00,0X00,0X02,0X00,0X93,0XFA,
0X2C,0X2A,0X02,0X5E,0X40,0X03,0X81,0XC0,0X06,0X00,0X00,0X00,0X00,0X00,0X00,0X00,
0X00,0X00,0X00,0X00,0X00,0X00,0X00,0X00,0X00,0X00,0XE0,0XF0,0X78,0X20,0XC7,0X00,
0X10,0X17,0X01,0XF0,0X04,0X20,0X00,0X00,0X00,0X00,0X00,0X10,0X02,0X20,0X00,0X00,
0X0F,0XE0,0X48,0X31,0X00,0X18,0X40,0X07,0X01,0X80,0X02,0X00,0X00,0X00,0X00,0X00,
0X00,0X00,0X00,0X00,0X00,0X00,0X00,0X00,0X00,0X00,0X00,0X00,0XD1,0XE0,0X70,0X0D,
0XC3,0XA8,0X04,0X04,0X00,0X7C,0X04,0X04,0X00,0X20,0X02,0X00,0X00,0X20,0X20,0X00,
0X00,0X00,0X37,0X80,0X38,0X08,0X08,0X31,0X08,0X07,0X03,0X00,0X01,0X00,0X00,0X00,
0X00,0X00,0X00,0X00,0X00,0X00,0X00,0X00,0X00,0X00,0X00,0X00,0X00,0X00,0XE9,0XC0,
0X70,0X01,0XE3,0X80,0X41,0X01,0X09,0X7E,0X60,0X40,0X08,0X81,0X10,0X00,0X00,0X00,
0X00,0X00,0X40,0X00,0XBF,0X10,0X7A,0X44,0X07,0XF9,0X24,0X07,0X06,0X00,0X04,0X00,
0X00,0X00,0X00,0X00,0X00,0X00,0X00,0X00,0X00,0X00,0X00,0X00,0X00,0X00,0X00,0X01,
0X83,0X80,0X38,0X02,0XE3,0XC0,0X28,0X40,0X8B,0X47,0XC0,0X00,0X00,0X00,0X00,0X20,
0X80,0X00,0X00,0X20,0X08,0X01,0XF6,0X18,0X38,0X50,0X10,0XF8,0X10,0X0E,0X00,0X00,
0X00,0X00,0X00,0X00,0X00,0X00,0X00,0X00,0X00,0X00,0X00,0X00,0X00,0X00,0X00,0X00,
0X00,0X01,0XC3,0X20,0X3C,0X8A,0X61,0XC0,0X24,0X21,0XD0,0X07,0XF0,0X00,0X00,0X00,
0X20,0X04,0X00,0X40,0X02,0X00,0X00,0X03,0XEC,0X10,0X78,0X0A,0X43,0XD1,0X05,0X9E,
0X00,0X00,0X00,0X00,0X00,0X00,0X00,0X00,0X00,0X00,0X00,0X00,0X00,0X00,0X00,0X00,
0X00,0X00,0X00,0X01,0XCF,0X00,0X18,0X02,0XF1,0XFA,0X05,0X71,0X10,0X01,0XEC,0X00,
0X00,0X00,0X00,0X40,0X00,0X00,0X00,0X00,0X02,0X0F,0XF2,0X0D,0XF8,0X54,0X0F,0XF8,
0X10,0X9E,0X00,0X00,0X00,0X00,0X00,0X00,0X00,0X00,0X00,0X00,0X00,0X00,0X00,0X00,
0X00,0X00,0X00,0X00,0X00,0X01,0XAC,0X00,0X1C,0X40,0X70,0XF2,0X80,0X60,0X00,0XA0,
0X7F,0X00,0XC0,0X00,0X00,0X24,0X10,0X00,0X00,0X00,0X00,0X1F,0XE3,0X00,0XFC,0X8A,
0X8F,0XE0,0X28,0XDC,0X00,0X00,0X00,0X00,0X00,0X00,0X00,0X00,0X00,0X00,0X00,0X00,
0X00,0X00,0X00,0X00,0X00,0X00,0X00,0X01,0X18,0X00,0X1E,0X08,0X68,0X70,0X08,0X30,
0X0D,0XD8,0X1F,0X80,0X08,0X00,0X08,0X00,0X00,0X00,0X00,0X20,0X00,0X7F,0XEB,0X20,
0XDC,0X00,0X1F,0XE0,0X00,0X1C,0X00,0X00,0X00,0X00,0X00,0X00,0X00,0X00,0X00,0X00,
0X00,0X00,0X00,0X00,0X00,0X00,0X00,0X00,0X00,0X03,0X30,0X00,0X0F,0X01,0X3C,0X70,
0X12,0X30,0XE4,0X80,0X07,0XF0,0X02,0X00,0X00,0X00,0X02,0X20,0X04,0X20,0X00,0X7F,
0XE1,0X00,0X9C,0X85,0X1F,0XF5,0XB0,0X18,0X00,0X00,0X00,0X00,0X00,0X00,0X00,0X00,
0X00,0X00,0X00,0X00,0X00,0X00,0X00,0X00,0X00,0X00,0X00,0X07,0X60,0X00,0X07,0X40,
0X7C,0X38,0X73,0X30,0XC4,0X41,0X08,0X78,0X00,0X08,0X00,0X00,0X02,0X00,0X01,0X00,
0X01,0XFF,0XC4,0X20,0X9D,0X00,0X3F,0XF2,0XA0,0X3C,0X00,0X00,0X00,0X00,0X00,0X00,
0X00,0X00,0X00,0X00,0X00,0X00,0X00,0X00,0X00,0X00,0X00,0X00,0X00,0X07,0XC0,0X20,
0X27,0XC0,0XFC,0X1C,0X00,0X38,0X50,0X10,0X02,0X3C,0X00,0X04,0X00,0X00,0X40,0X00,
0X41,0X00,0X0F,0XFF,0XD0,0X0B,0X5C,0X05,0XF9,0XE8,0X00,0X38,0X00,0X00,0X00,0X00,
0X00,0X00,0X00,0X00,0X00,0X00,0X00,0X00,0X00,0X00,0X00,0X00,0X00,0X00,0X00,0X07,
0X80,0X00,0X01,0X80,0X3C,0X1C,0X03,0X9F,0X60,0X20,0X08,0X5F,0X00,0X00,0X00,0X00,
0X00,0X01,0X00,0X00,0X3F,0X7F,0XC0,0X43,0X38,0X00,0X79,0XF8,0X02,0X30,0X00,0X00,
0X00,0X00,0X00,0X00,0X00,0X00,0X00,0X00,0X00,0X00,0X00,0X00,0X00,0X00,0X00,0X00,
0X00,0X0E,0X00,0X00,0X01,0XC1,0X9C,0X0E,0XD0,0X7F,0XC0,0X30,0X01,0X0B,0X78,0X00,
0X00,0X00,0X20,0X00,0X00,0X20,0X7F,0XFF,0XC0,0X03,0X3E,0X20,0XF0,0XFD,0X90,0X70,
0X00,0X00,0X00,0X00,0X00,0X00,0X00,0X00,0X00,0X00,0X00,0X00,0X00,0X00,0X00,0X00,
0X00,0X00,0X00,0X18,0X00,0X00,0X01,0XE0,0X3C,0X07,0X00,0X39,0XF0,0X05,0X64,0X10,
0XF8,0X22,0X00,0X00,0X00,0X00,0X00,0X01,0XFF,0XF3,0XC5,0X07,0X1B,0X01,0XE0,0X7C,
0XC0,0XF0,0X00,0X00,0X00,0X00,0X00,0X00,0X00,0X00,0X00,0X00,0X00,0X00,0X00,0X00,
0X00,0X00,0X00,0X00,0X00,0X20,0X00,0X00,0X00,0XF8,0X38,0X07,0X04,0X7F,0XF8,0X29,
0X20,0XC0,0X3F,0XC0,0X00,0X08,0X00,0X00,0X00,0X16,0XFF,0X81,0XC1,0XCF,0XBF,0X2B,
0XC0,0X1C,0X41,0XE0,0X00,0X00,0X00,0X00,0X00,0X00,0X00,0X00,0X00,0X00,0X00,0X00,
0X00,0X00,0X00,0X00,0X00,0X00,0X00,0X00,0X00,0X00,0X00,0X78,0X3C,0X03,0XA0,0X3F,
0XF9,0X10,0X58,0X02,0X3F,0XF0,0X80,0X00,0X00,0X00,0X00,0X1F,0XFF,0XCF,0XC4,0X0A,
0X3E,0X13,0XC0,0X3C,0X01,0XE0,0X00,0X00,0X00,0X00,0X00,0X00,0X00,0X00,0X00,0X00,
0X00,0X00,0X00,0X00,0X00,0X00,0X00,0X00,0X00,0X00,0X00,0X00,0X00,0X7C,0X1C,0X03,
0XC8,0X5F,0XFC,0X01,0X10,0X00,0X1F,0XFA,0X01,0X00,0X00,0X20,0X00,0X7F,0XFD,0X05,
0XEC,0X8E,0X3E,0X03,0X00,0X3E,0X23,0XE0,0X00,0X00,0X00,0X00,0X00,0X00,0X00,0X00,
0X00,0X00,0X00,0X00,0X00,0X00,0X00,0X00,0X00,0X00,0X00,0X00,0X00,0X00,0X00,0X3E,
0X1C,0X01,0XE6,0X07,0XFF,0X02,0X02,0X13,0X9B,0XFF,0X80,0X12,0X00,0X04,0X41,0XFF,
0XFC,0X3B,0X4A,0X88,0X3C,0X07,0X00,0X36,0X03,0XC0,0X00,0X00,0X00,0X00,0X00,0X00,
0X00,0X00,0X00,0X00,0X00,0X00,0X00,0X00,0X00,0X00,0X00,0X00,0X00,0X00,0X00,0X00,
0X00,0X0F,0X1C,0X01,0XE9,0XA3,0XFF,0X82,0X24,0X0A,0X1F,0XFF,0XE0,0X00,0X08,0X40,
0X27,0XFF,0XF1,0XEB,0XE1,0X38,0X7C,0X0E,0X00,0X1E,0X27,0XC0,0X00,0X00,0X00,0X00,
0X00,0X00,0X00,0X00,0X00,0X00,0X00,0X00,0X00,0X00,0X00,0X00,0X00,0X00,0X00,0X00,
0X00,0X00,0X00,0X0F,0X8C,0X00,0XF0,0XAF,0XFF,0X85,0X48,0X80,0XBF,0XEF,0XF8,0X00,
0X00,0X10,0X2F,0XFF,0XDE,0X77,0XC8,0X38,0X38,0X1E,0X00,0X1F,0X47,0XE0,0X00,0X00,
0X00,0X00,0X00,0X00,0X00,0X00,0X00,0X00,0X00,0X00,0X00,0X00,0X00,0X00,0X00,0X00,
0X00,0X00,0X00,0X00,0X00,0X07,0X8A,0X00,0X75,0X13,0XFF,0XC2,0X0A,0X14,0X1F,0XFF,
0XFF,0X00,0X80,0X07,0XFF,0XFF,0XF2,0X0B,0XE0,0X38,0X78,0X18,0X00,0X0F,0X07,0XE0,
0X00,0X00,0X00,0X00,0X00,0X00,0X00,0X00,0X00,0X00,0X00,0X00,0X00,0X00,0X00,0X00,
0X00,0X00,0X00,0X00,0X00,0X00,0X00,0X03,0XE6,0X00,0X38,0XD3,0XFF,0XC0,0X80,0X3E,
0X9F,0XFF,0XFF,0XF0,0X80,0X0B,0XFF,0XFF,0XC2,0XD7,0XFF,0XF8,0X38,0X30,0X00,0X07,
0XCF,0XC0,0X00,0X00,0X00,0X00,0X00,0X00,0X00,0X00,0X00,0X00,0X00,0X00,0X00,0X00,
0X00,0X00,0X00,0X00,0X00,0X00,0X00,0X00,0X00,0X01,0XF6,0X00,0X38,0XE8,0XDF,0X70,
0X03,0X14,0X1F,0XFF,0XFF,0XF0,0X01,0XFF,0XFE,0XBA,0X08,0X07,0XFF,0XF8,0X79,0X70,
0X00,0X07,0X1F,0XC0,0X00,0X00,0X00,0X00,0X00,0X00,0X00,0X00,0X00,0X00,0X00,0X00,
0X00,0X00,0X00,0X00,0X00,0X00,0X00,0X00,0X00,0X00,0X00,0X00,0X77,0X00,0X1C,0X0D,
0XDF,0X98,0X01,0X14,0XCF,0XFF,0XFF,0XFC,0X03,0XFF,0XFF,0XC2,0X71,0X93,0XE4,0XF8,
0X38,0XC8,0X00,0X03,0X87,0X00,0X00,0X00,0X00,0X00,0X00,0X00,0X00,0X00,0X00,0X00,
0X00,0X00,0X00,0X00,0X00,0X00,0X00,0X00,0X00,0X00,0X00,0X00,0X00,0X00,0X7F,0X00,
0X1C,0X43,0XDF,0XDC,0X80,0X00,0X0F,0XFF,0XFF,0XFF,0XF7,0XFF,0XFF,0XDB,0X53,0X01,
0XC0,0X00,0X39,0XC0,0X00,0X03,0X8F,0X00,0X00,0X00,0X00,0X00,0X00,0X00,0X00,0X00,
0X00,0X00,0X00,0X00,0X00,0X00,0X00,0X00,0X00,0X00,0X00,0X00,0X00,0X00,0X00,0X00,
0X1F,0X80,0X0E,0X36,0XEF,0XCC,0XB1,0X00,0X8F,0XFF,0XFF,0XF7,0XDB,0XFF,0XFF,0XE8,
0XA5,0X03,0X8A,0X00,0X71,0X80,0X00,0X01,0XCE,0X00,0X00,0X00,0X00,0X00,0X00,0X00,
0X00,0X00,0X00,0X00,0X00,0X00,0X00,0X00,0X00,0X00,0X00,0X00,0X00,0X00,0X00,0X00,
0X00,0X00,0X2F,0XC0,0X05,0XF0,0XEF,0XCE,0X00,0X30,0X0E,0XBF,0XFF,0XFF,0XFF,0XFF,
0XFD,0XC1,0X94,0X09,0XC0,0X00,0X22,0X00,0X00,0X01,0XCC,0X00,0X00,0X00,0X00,0X00,
0X00,0X00,0X00,0X00,0X00,0X00,0X00,0X00,0X00,0X00,0X00,0X00,0X00,0X00,0X00,0X00,
0X00,0X00,0X00,0X00,0X17,0XC0,0X07,0XF8,0XE7,0XE3,0X16,0X00,0X0F,0XF7,0XFF,0XFF,
0XFF,0XFF,0XFE,0X31,0X71,0XD3,0X80,0X00,0X3E,0X00,0X00,0X00,0XCC,0X00,0X00,0X00,
0X00,0X00,0X00,0X00,0X00,0X00,0X00,0X00,0X00,0X00,0X00,0X00,0X00,0X00,0X00,0X00,
0X00,0X00,0X00,0X00,0X00,0X00,0X00,0X40,0X0F,0XF8,0XF3,0XE3,0X84,0X34,0X0F,0XAD,
0XAF,0XFF,0XFF,0XFF,0XFD,0X0B,0XB0,0X41,0XD0,0X08,0X1C,0X00,0X00,0X80,0XFC,0X00,
0X00,0X00,0X00,0X00,0X00,0X00,0X00,0X00,0X00,0X00,0X00,0X00,0X00,0X00,0X00,0X00,
0X00,0X00,0X00,0X00,0X00,0X00,0X00,0X10,0X00,0X00,0X2F,0XFC,0X77,0XD1,0XC0,0X40,
0X4E,0X5C,0XFF,0XFF,0XFF,0XFF,0XC0,0XCD,0X33,0X11,0XF2,0X1C,0X30,0X00,0X00,0X00,
0XFC,0X00,0X00,0X00,0X00,0X00,0X00,0X00,0X00,0X00,0X00,0X00,0X00,0X00,0X00,0X00,
0X00,0X00,0X00,0X00,0X00,0X00,0X00,0X00,0X00,0X00,0X01,0X00,0X03,0X06,0X7D,0XF9,
0XF0,0X40,0X1E,0X8F,0X77,0XFF,0XFF,0XFF,0XD0,0XB3,0X0C,0X0F,0XC4,0XA1,0XF0,0X00,
0X00,0X08,0X38,0X00,0X00,0X00,0X00,0X00,0X00,0X00,0X00,0X00,0X00,0X00,0X00,0X00,
0X00,0X00,0X00,0X00,0X00,0X00,0X00,0X00,0X00,0X00,0X00,0X00,0X00,0X00,0X00,0X02,
0X38,0XF0,0XFF,0X55,0XFE,0XD5,0X35,0XFF,0X5E,0XFF,0X0B,0X40,0XC0,0X83,0XC0,0X01,
0XF0,0X00,0X00,0X00,0X38,0X00,0X00,0X00,0X00,0X00,0X00,0X00,0X00,0X00,0X00,0X00,
0X00,0X00,0X00,0X00,0X00,0X00,0X00,0X00,0X00,0X00,0X00,0X00,0X00,0X00,0X00,0X00,
0X00,0X03,0X78,0XF8,0X3F,0XFF,0XFF,0XDC,0X85,0X57,0XFF,0XFA,0X05,0X56,0X50,0X8F,
0XDE,0X81,0XF0,0X00,0X00,0X00,0X18,0X00,0X00,0X00,0X00,0X00,0X00,0X00,0X00,0X00,
0X00,0X00,0X00,0X00,0X00,0X00,0X00,0X00,0X00,0X00,0X00,0X00,0X00,0X00,0X00,0X00,
0X00,0X00,0X00,0X01,0XB8,0X38,0X0F,0XB5,0X1F,0XD9,0X88,0X9F,0XFD,0XFA,0XD4,0X02,
0X03,0XA9,0XF1,0X02,0X38,0X00,0X00,0X00,0X02,0X00,0X00,0X00,0X00,0X00,0X00,0X00,
0X00,0X00,0X00,0X00,0X00,0X00,0X00,0X00,0X00,0X00,0X00,0X00,0X00,0X00,0X00,0X00,
0X00,0X00,0X00,0X00,0X00,0X00,0XF8,0X1E,0X0E,0X40,0X1F,0X91,0XCA,0X0B,0XF7,0XD8,
0X7C,0X2A,0X08,0X61,0XE8,0X03,0XCC,0X00,0X00,0X00,0X00,0X00,0X00,0X00,0X00,0X00,
0X00,0X00,0X00,0X00,0X00,0X00,0X00,0X00,0X00,0X00,0X00,0X00,0X00,0X00,0X00,0X00,
0X00,0X00,0X00,0X00,0X00,0X00,0X00,0X00,0X78,0X0F,0X1E,0X00,0X9C,0X81,0X14,0X4B,
0X3B,0XC1,0XE8,0XA1,0X25,0X03,0XFE,0X43,0X2E,0X00,0X00,0X00,0X00,0X00,0X00,0X00,
0X00,0X00,0X00,0X00,0X00,0X00,0X00,0X00,0X00,0X00,0X00,0X00,0X00,0X00,0X00,0X00,
0X00,0X00,0X00,0X00,0X00,0X00,0X00,0X00,0X00,0X00,0X78,0X00,0X0C,0X10,0X7F,0X0C,
0X4A,0X8A,0XF3,0X24,0X22,0X0A,0X80,0X99,0XFC,0X24,0X17,0X00,0X00,0X00,0X00,0X00,
0X00,0X00,0X00,0X00,0X00,0X00,0X00,0X00,0X00,0X00,0X00,0X00,0X00,0X00,0X00,0X00,
0X00,0X00,0X00,0X00,0X00,0X00,0X00,0X00,0X00,0X00,0X00,0X00,0X38,0X00,0X18,0X00,
0XFE,0X71,0X16,0X5D,0XC5,0X91,0X21,0X96,0X89,0X8B,0XF8,0X04,0X11,0X80,0X00,0X00,
0X00,0X00,0X00,0X00,0X00,0X00,0X00,0X00,0X00,0X00,0X00,0X00,0X00,0X00,0X00,0X00,
0X00,0X00,0X00,0X00,0X00,0X00,0X00,0X00,0X00,0X00,0X00,0X00,0X00,0X00,0X18,0X00,
0X38,0X03,0XBE,0X00,0X18,0X2A,0X02,0X50,0X94,0XE2,0X29,0X91,0XF0,0X0C,0X00,0XE0,
0X00,0X00,0X00,0X00,0X00,0X00,0X00,0X00,0X00,0X00,0X00,0X00,0X00,0X00,0X00,0X00,
0X00,0X00,0X00,0X00,0X00,0X00,0X00,0X00,0X00,0X00,0X00,0X00,0X00,0X00,0X00,0X00,
0X18,0X00,0X38,0X33,0XBE,0X07,0X4E,0X0D,0XBC,0X10,0X21,0X00,0X10,0X81,0XF0,0XB8,
0X03,0X70,0X00,0X00,0X00,0X00,0X00,0X00,0X00,0X00,0X00,0X00,0X00,0X00,0X00,0X00,
0X00,0X00,0X00,0X00,0X00,0X00,0X00,0X00,0X00,0X00,0X00,0X00,0X00,0X00,0X00,0X00,
0X00,0X00,0X0C,0X00,0X71,0XAF,0X3E,0X04,0X8B,0XDC,0X04,0XA0,0X63,0X99,0X32,0X82,
0XF0,0XB2,0X82,0X10,0X00,0X00,0X00,0X00,0X00,0X00,0X00,0X00,0X00,0X00,0X00,0X00,
0X00,0X00,0X00,0X00,0X00,0X00,0X00,0X00,0X00,0X00,0X00,0X00,0X00,0X00,0X00,0X00,
0X00,0X00,0X00,0X00,0X04,0X00,0X72,0XFD,0XBE,0X01,0XD2,0X6C,0X20,0X52,0X05,0X80,
0X3A,0X90,0XF2,0XB0,0X07,0XFE,0X00,0X00,0X00,0X00,0X00,0X00,0X00,0X00,0X00,0X00,
0X00,0X00,0X00,0X00,0X00,0X00,0X00,0X00,0X00,0X00,0X00,0X00,0X00,0X00,0X00,0X00,
0X00,0X00,0X00,0X00,0X00,0X00,0X04,0X00,0XF0,0XF6,0X3E,0X01,0X47,0XED,0X48,0X65,
0X41,0X84,0X15,0X08,0XF2,0XE0,0X07,0XB7,0X18,0X00,0X00,0X00,0X00,0X00,0X00,0X00,
0X00,0X00,0X00,0X00,0X00,0X00,0X00,0X00,0X00,0X00,0X00,0X00,0X00,0X00,0X00,0X00,
0X00,0X00,0X00,0X00,0X00,0X00,0X00,0X00,0X06,0X00,0XF4,0X71,0XFE,0X21,0XCC,0XE1,
0XB1,0XBA,0X40,0X98,0X04,0X40,0XEC,0XE8,0X47,0X1B,0X8C,0X04,0X00,0X00,0X00,0X00,
0X00,0X00,0X00,0X00,0X00,0X00,0X00,0X00,0X00,0X00,0X00,0X00,0X00,0X00,0X00,0X00,
0X00,0X00,0X00,0X00,0X00,0X00,0X00,0X00,0X00,0X00,0X02,0X01,0XE2,0XF3,0XEC,0X00,
0X5C,0X78,0XC2,0XA0,0X11,0X00,0X23,0X69,0XF3,0XC0,0X06,0XEF,0XE3,0X00,0X00,0X00,
0X00,0X00,0X00,0X00,0X00,0X00,0X00,0X00,0X00,0X00,0X00,0X00,0X00,0X00,0X00,0X00,
0X00,0X00,0X00,0X00,0X00,0X00,0X00,0X00,0X00,0X00,0X00,0X00,0X03,0X01,0XE0,0XF9,
0XBE,0X48,0X33,0X60,0XA1,0X8A,0X86,0XE0,0X48,0X10,0XF7,0XD2,0X06,0XA5,0XE4,0X80,
0X00,0X00,0X00,0X00,0X00,0X00,0X00,0X00,0X00,0X00,0X00,0X00,0X00,0X00,0X00,0X00,
0X00,0X00,0X00,0X00,0X00,0X00,0X00,0X00,0X00,0X00,0X00,0X00,0X00,0X00,0X00,0X81,
0XC0,0XFA,0X0A,0X00,0X30,0XD8,0XA4,0XB2,0X15,0X10,0X40,0X48,0XF3,0XD0,0X06,0X23,
0X78,0XE0,0X00,0X00,0X00,0X00,0X00,0X00,0X00,0X00,0X00,0X00,0X00,0X00,0X00,0X00,
0X00,0X00,0X00,0X00,0X00,0X00,0X00,0X00,0X00,0X00,0X00,0X00,0X00,0X00,0X00,0X00,
0X00,0X01,0XF8,0XB9,0XEC,0X00,0X0C,0X8E,0X30,0XA0,0X08,0X01,0X00,0X04,0XEB,0XA0,
0X9F,0X9B,0XF4,0X38,0X00,0X00,0X00,0X00,0X00,0X00,0X00,0X00,0X00,0X00,0X00,0X00,
0X00,0X00,0X00,0X00,0X00,0X00,0X00,0X00,0X00,0X00,0X00,0X00,0X00,0X00,0X00,0X00,
0X00,0X00,0X00,0X03,0XDA,0X1C,0XED,0X02,0X05,0X01,0X65,0X4C,0X8C,0XE0,0XB0,0X84,
0X6F,0X08,0X07,0X1B,0XBC,0X0E,0X00,0X00,0X00,0X00,0X00,0X00,0X00,0X00,0X00,0X00,
0X00,0X00,0X00,0X00,0X00,0X00,0X00,0X00,0X00,0X00,0X00,0X00,0X00,0X00,0X00,0X00,
0X00,0X00,0X00,0X00,0X00,0X07,0XBD,0X1E,0XEA,0X80,0X02,0X63,0X45,0X6C,0X88,0X51,
0X00,0X02,0X6E,0X08,0X2F,0X77,0XEF,0X8B,0X00,0X00,0X00,0X00,0X00,0X00,0X00,0X00,
0X00,0X00,0X00,0X00,0X00,0X00,0X00,0X00,0X00,0X00,0X00,0X00,0X00,0X00,0X00,0X00,
0X00,0X00,0X00,0X00,0X00,0X00,0X00,0X07,0XDD,0X2F,0XE8,0X40,0X00,0X10,0X46,0X19,
0X43,0X07,0X01,0X14,0X3E,0X10,0X75,0XFF,0XDF,0X81,0XC0,0X00,0X00,0X00,0X00,0X00,
0X00,0X00,0X00,0X00,0X00,0X00,0X00,0X00,0X00,0X00,0X00,0X00,0X00,0X00,0X00,0X00,
0X00,0X00,0X00,0X00,0X00,0X00,0X00,0X00,0X00,0X0E,0XBE,0X0F,0XF8,0X80,0X10,0XD1,
0X7B,0X08,0X76,0X6C,0X0A,0X40,0X78,0X00,0X07,0XF6,0XE3,0XCE,0X30,0X00,0X00,0X00,
0X00,0X00,0X00,0X00,0X00,0X00,0X00,0X00,0X00,0X00,0X00,0X00,0X00,0X00,0X00,0X00,
0X00,0X00,0X00,0X00,0X00,0X00,0X00,0X00,0X00,0X00,0X00,0XDF,0X3C,0X07,0XF8,0X40,
0X28,0X20,0XC0,0XA0,0XA6,0X80,0X31,0X08,0X78,0X00,0X05,0X7F,0XD7,0XF2,0X38,0X00,
0X00,0X00,0X00,0X00,0X00,0X00,0X00,0X00,0X00,0X00,0X00,0X00,0X00,0X00,0X00,0X00,
0X00,0X00,0X00,0X00,0X00,0X00,0X00,0X00,0X00,0X00,0X00,0X00,0X00,0XCE,0XFE,0X03,
0XF0,0X00,0X00,0X01,0X53,0XC0,0X86,0XB2,0X00,0X98,0XE0,0X00,0X02,0XE7,0XDB,0XFC,
0X03,0X00,0X00,0X00,0X00,0X00,0X00,0X00,0X00,0X00,0X00,0X00,0X00,0X00,0X00,0X00,
0X00,0X00,0X00,0X00,0X00,0X00,0X00,0X00,0X00,0X00,0X00,0X00,0X00,0X00,0X43,0X9F,
0XEE,0X03,0XF0,0X00,0X00,0X00,0X20,0X4A,0X04,0X10,0X02,0X41,0XE0,0X84,0X26,0XD6,
0X7E,0X7B,0X04,0X80,0X00,0X00,0X00,0X00,0X00,0X00,0X00,0X00,0X00,0X00,0X00,0X00,
0X00,0X00,0X00,0X00,0X00,0X00,0X00,0X00,0X00,0X00,0X00,0X00,0X00,0X00,0X00,0X00,
0X46,0X5C,0X06,0X02,0XF7,0X10,0X20,0X03,0XCC,0XA8,0XDD,0X84,0X80,0X03,0XC0,0X00,
0X03,0XFF,0XD6,0XF7,0X89,0X60,0X00,0X00,0X00,0X00,0X00,0X00,0X00,0X00,0X00,0X00,
0X00,0X00,0X00,0X00,0X00,0X00,0X00,0X00,0X00,0X00,0X00,0X00,0X00,0X00,0X00,0X00,
0X00,0X00,0X0C,0X97,0XEE,0X00,0XF4,0X00,0X80,0X21,0X03,0XC8,0X6C,0X80,0X04,0X87,
0X80,0X00,0X02,0XFB,0X1C,0XAF,0XF0,0X30,0X00,0X00,0X00,0X00,0X00,0X00,0X00,0X00,
0X00,0X00,0X00,0X00,0X00,0X00,0X00,0X00,0X00,0X00,0X00,0X00,0X00,0X00,0X00,0X00,
0X00,0X00,0X00,0X00,0X11,0XFF,0X76,0X06,0X78,0X81,0X50,0X00,0XB8,0X93,0X00,0X04,
0X08,0X2E,0X00,0X80,0X02,0XFE,0XCE,0XFF,0XFC,0X07,0X00,0X00,0X00,0X00,0X00,0X00,
0X00,0X00,0X00,0X00,0X00,0X00,0X00,0X00,0X00,0X00,0X00,0X00,0X00,0X00,0X00,0X00,
0X00,0X00,0X00,0X00,0X00,0X00,0X03,0XFF,0X8B,0X04,0X39,0XC0,0X80,0X01,0X19,0XA8,
0XE1,0X02,0X12,0X1E,0X00,0X00,0X06,0XD5,0XB5,0XDF,0XFE,0X41,0X80,0X00,0X00,0X00,
0X00,0X00,0X00,0X00,0X00,0X00,0X00,0X00,0X00,0X00,0X00,0X00,0X00,0X00,0X00,0X00,
0X00,0X00,0X00,0X00,0X00,0X00,0X00,0X00,0X0F,0XFC,0XFD,0X00,0X3C,0X00,0X41,0X82,
0X86,0X6F,0X52,0X02,0X01,0X3C,0X00,0X40,0X03,0X9F,0XDD,0XFE,0XFF,0XE8,0X60,0X00,
0X00,0X00,0X00,0X00,0X00,0X00,0X00,0X00,0X00,0X00,0X00,0X00,0X00,0X00,0X00,0X00,
0X00,0X00,0X00,0X00,0X00,0X00,0X00,0X00,0X00,0X00,0XFF,0XF5,0XDE,0X00,0X1C,0X00,
0X00,0X44,0X00,0XE0,0X00,0X01,0X80,0X78,0X22,0X08,0X02,0XC7,0XEE,0XFD,0XBD,0XFA,
0X18,0X00,0X00,0X00,0X00,0X00,0X00,0X00,0X00,0X00,0X00,0X00,0X00,0X00,0X00,0X00,
0X00,0X00,0X00,0X00,0X00,0X00,0X00,0X00,0X00,0X00,0X00,0X00,0XFF,0XF7,0XAE,0X00,
0X0F,0X81,0X10,0X00,0X10,0X02,0X00,0X80,0X22,0XE1,0X09,0X01,0X41,0XFE,0XF3,0XFB,
0XC5,0XFE,0X02,0X00,0X00,0X00,0X00,0X00,0X00,0X00,0X00,0X00,0X00,0X00,0X00,0X00,
0X00,0X00,0X00,0X00,0X00,0X00,0X00,0X00,0X00,0X00,0X00,0X00,0X00,0X07,0XFF,0XFF,
0XCE,0X40,0X37,0X10,0X02,0X00,0X40,0X00,0XC4,0X00,0X05,0XE0,0X10,0X23,0X82,0X3B,
0XBE,0XDD,0XFF,0X3F,0XA0,0X00,0X00,0X00,0X00,0X00,0X00,0X00,0X00,0X00,0X00,0X00,
0X00,0X00,0X00,0X00,0X00,0X00,0X00,0X00,0X00,0X00,0X00,0X00,0X00,0X00,0X00,0X7F,
0XFA,0XDE,0X9E,0X00,0X03,0X98,0X00,0X00,0X02,0X00,0X05,0X10,0X01,0XC0,0X00,0X00,
0X04,0XD9,0X57,0X8F,0XB5,0X3F,0XFD,0X50,0X00,0X00,0X00,0X00,0X00,0X00,0X00,0X00,
0X00,0X00,0X00,0X00,0X00,0X00,0X00,0X00,0X00,0X00,0X00,0X00,0X00,0X00,0X02,0X00,
0X00,0XFF,0XDF,0XF1,0X7E,0X02,0X43,0X80,0X0A,0X62,0X80,0X00,0X8A,0X10,0X07,0X80,
0X04,0X00,0X06,0X9B,0X01,0X7E,0XFC,0XA8,0XFF,0XE0,0X00,0X00,0X00,0X00,0X00,0X00,
0X00,0X00,0X00,0X00,0X00,0X00,0X00,0X00,0X00,0X00,0X00,0X00,0X00,0X00,0X00,0X00,
0X00,0X00,0X0B,0XDE,0XBD,0XDF,0XF2,0X19,0X90,0XEA,0X88,0X01,0X00,0X62,0X00,0X00,
0X0F,0X20,0X00,0X00,0X45,0X9D,0XCF,0XFD,0XC4,0XC4,0X5F,0XF8,0X00,0X00,0X00,0X00,
0X00,0X00,0X00,0X00,0X00,0X00,0X00,0X00,0X00,0X00,0X00,0X00,0X00,0X00,0X00,0X00,
0X00,0X00,0X00,0X00,0X3D,0XFD,0XEE,0XFE,0X4C,0X09,0X00,0X60,0X00,0X00,0X02,0X00,
0X10,0X00,0X1E,0X31,0X62,0X00,0X86,0X65,0X7B,0XFF,0XC2,0X1D,0X1F,0XFC,0X00,0X00,
0X00,0X00,0X00,0X00,0X00,0X00,0X00,0X00,0X00,0X00,0X00,0X00,0X00,0X00,0X00,0X00,
0X00,0X00,0X00,0X00,0X00,0X01,0XFF,0XE3,0X7C,0X35,0X46,0X01,0X31,0XE0,0X40,0XA8,
0X00,0X40,0X20,0X04,0X38,0X58,0X08,0X00,0X05,0XFD,0X3F,0XBF,0X88,0X60,0XDB,0XDF,
0XC4,0X00,0X00,0X00,0X00,0X00,0X00,0X00,0X00,0X00,0X00,0X00,0X00,0X00,0X00,0X00,
0X00,0X00,0X00,0X00,0X00,0X00,0X00,0X3F,0XDE,0XE5,0X75,0XBB,0X4F,0X08,0X0C,0X38,
0X0A,0X00,0X08,0X82,0X02,0XC0,0X78,0X00,0X00,0X00,0X0C,0XDF,0XE7,0XBB,0X26,0X19,
0X62,0X6F,0XE0,0X00,0X00,0X00,0X00,0X00,0X00,0X00,0X00,0X00,0X00,0X00,0X00,0X00,
0X00,0X00,0X00,0X00,0X00,0X00,0X00,0X02,0XD7,0XFF,0XEC,0X6E,0X47,0X79,0XC3,0X40,
0X50,0X1E,0X80,0X00,0X80,0X80,0X00,0X41,0XE1,0X04,0X40,0X00,0X0A,0XFF,0XDB,0X7C,
0XD0,0X06,0XA1,0X8B,0XFC,0X00,0X00,0X00,0X00,0X00,0X00,0X00,0X00,0X00,0X00,0X00,
0X00,0X00,0X00,0X00,0X00,0X00,0X00,0X00,0X00,0X17,0XFF,0XFF,0XFE,0X8F,0X06,0XBD,
0X1F,0X00,0X82,0X8E,0X20,0X00,0X80,0X00,0X00,0X07,0XC0,0X40,0X00,0X00,0X08,0XE7,
0XEF,0XF7,0XD7,0X96,0X7D,0X11,0X5F,0X40,0X00,0X00,0X00,0X00,0X00,0X00,0X00,0X00,
0X00,0X00,0X00,0X00,0X00,0X00,0X00,0X00,0X00,0X00,0X00,0XFF,0XFF,0XFE,0XBF,0XFF,
0X36,0XDF,0XBF,0X04,0X20,0X23,0X02,0X00,0X34,0X00,0X07,0X53,0X45,0X00,0X00,0X00,
0X1F,0XEF,0X5E,0XEC,0X21,0XEE,0X77,0X67,0X8F,0XFE,0X00,0X00,0X00,0X00,0X00,0X00,
0X00,0X00,0X00,0X00,0X00,0X00,0X00,0X00,0X00,0X00,0X00,0X00,0X03,0XED,0XFE,0XFF,
0X87,0XB6,0X69,0XEF,0X99,0X00,0X00,0X81,0XD0,0X00,0X44,0XA0,0X00,0X57,0X00,0X10,
0X80,0X00,0X1F,0X1E,0XF5,0XFB,0XFB,0X30,0X3F,0XFC,0X57,0XFF,0X00,0X00,0X00,0X00,
0X00,0X00,0X00,0X00,0X00,0X00,0X00,0X00,0X00,0X00,0X00,0X00,0X00,0X00,0X0F,0XD0,
0X7F,0XA5,0X1F,0XBE,0X83,0X6B,0XCF,0X0C,0X20,0X01,0XE1,0X8D,0X10,0X40,0X00,0X0C,
0X00,0X00,0X00,0X00,0X16,0XE5,0XF3,0XFB,0X9A,0XFF,0X06,0X88,0XBF,0XFF,0XE0,0X00,
0X00,0X00,0X00,0X00,0X00,0X00,0X00,0X00,0X00,0X00,0X00,0X00,0X00,0X00,0X01,0XFF,
0XFF,0X90,0X7A,0XD9,0X98,0X93,0XD6,0X7F,0XEF,0X90,0X00,0X00,0X60,0XC0,0X00,0X28,
0X50,0X1C,0X00,0X06,0X40,0X00,0X39,0XE6,0XFF,0XBF,0XC0,0X84,0X42,0XF2,0X77,0XC3,
0XF0,0X00,0X00,0X00,0X00,0X00,0X00,0X00,0X00,0X00,0X00,0X00,0X00,0X00,0X00,0X00,
0X07,0XFF,0XFF,0X01,0X7A,0X12,0XDD,0XE8,0X9B,0X91,0XEB,0X00,0X20,0X00,0X78,0X02,
0X08,0X00,0X00,0X39,0X10,0X40,0X00,0X00,0X3C,0X67,0XFF,0XFF,0XFF,0XD9,0XEE,0X73,
0XFF,0X80,0X78,0X00,0X00,0X00,0X00,0X00,0X00,0X00,0X00,0X00,0X00,0X00,0X00,0X00,
0X00,0X00,0X0F,0XFF,0XF1,0X02,0X7C,0X66,0X70,0X58,0XA3,0X5D,0XFD,0XA0,0X84,0X02,
0X18,0X30,0X08,0X00,0XE7,0XE4,0X08,0X02,0X00,0X00,0X60,0XCD,0XFE,0X25,0X48,0X71,
0XB2,0XC2,0XCF,0X46,0X78,0X00,0X00,0X00,0X00,0X00,0X00,0X00,0X00,0X00,0X00,0X00,
0X00,0X00,0X00,0X00,0X0E,0X01,0X02,0X00,0X3D,0XE1,0XBF,0XB5,0XDF,0X8C,0XDC,0X81,
0X04,0X40,0X2C,0X02,0X00,0X11,0XFF,0XF0,0X20,0X40,0X00,0X00,0X7E,0X3F,0XF5,0X4E,
0XC7,0X67,0XCB,0XA5,0X7F,0X00,0X6C,0X00,0X00,0X00,0X00,0X00,0X00,0X00,0X00,0X00,
0X00,0X00,0X00,0X00,0X00,0X00,0X1C,0X40,0X44,0X08,0X7E,0XA1,0XF3,0XE5,0X21,0XFC,
0XE7,0XD0,0X00,0X50,0X06,0X00,0X40,0X03,0XFF,0X00,0X04,0X00,0X00,0X40,0X7A,0XDB,
0XF6,0X75,0XAB,0X7D,0XF1,0X0C,0X3E,0X08,0XF7,0XC0,0X00,0X00,0X00,0X00,0X00,0X00,
0X00,0X00,0X00,0X00,0X00,0X00,0X00,0X00,0X38,0X00,0X23,0X10,0X2F,0X9E,0XE7,0X38,
0X38,0X2D,0X77,0XC0,0X00,0X00,0X03,0XA2,0X05,0X07,0X8D,0X80,0X00,0X00,0X00,0X00,
0X6F,0X7F,0X3D,0XFE,0X90,0XF8,0XD6,0XC2,0X7C,0XF0,0X7F,0XFC,0X00,0X00,0X00,0X00,
0X00,0X00,0X00,0X00,0X00,0X00,0X00,0X00,0X00,0X00,0X78,0X00,0X2D,0X90,0XBF,0XDC,
0X53,0X01,0XF1,0XF7,0XF7,0XC0,0X00,0X08,0X03,0X82,0X19,0X4F,0X07,0X8A,0X80,0X00,
0X00,0X00,0XE6,0X7F,0XBF,0XFF,0X31,0X4F,0XE1,0X1A,0XF9,0XE1,0XFF,0XFF,0X00,0X00,
0X00,0X00,0X00,0X00,0X00,0X00,0X00,0X00,0X00,0X00,0X00,0X00,0X78,0X5B,0XFF,0X80,
0X1F,0XB4,0XFF,0X84,0XCD,0XBD,0XEB,0X00,0X00,0X00,0X80,0X80,0X40,0X0E,0X13,0XC2,
0X00,0X00,0X20,0X00,0XCE,0X7F,0X3D,0XD2,0X12,0X6E,0XAB,0X1B,0XF3,0XC7,0XFD,0XFF,
0XFE,0X40,0X00,0X00,0X00,0X00,0X00,0X00,};

/* USER CODE END 4 */

void Error_Handler(void)
{
}

/************************ (C) COPYRIGHT STMicroelectronics *****END OF FILE****/
